AUTOSAR XML (schema 00044)
package /COM/VECTOR/CFG/WORKFLOW/SYSDESC/SYNC
  system SYSTEM: category=ECU_EXTRACT
    system mapping MAPPINGS
      data-mappings:
        sender-receiver-to-signal-mapping={data-element=CComAbsMdl_stubs.COMPOSITIONTYPE.pp_SR_TxBattery_Voltage.Battery_Voltage, system-signal=Battery_Voltage}
        sender-receiver-to-signal-mapping={data-element=CComAbsMdl_stubs.COMPOSITIONTYPE.pp_SR_TxCurrentStateIC.CurrentStateIC, system-signal=CurrentStateIC}
        sender-receiver-to-signal-mapping={data-element=CComAbsMdl_stubs.COMPOSITIONTYPE.pp_SR_TxDebug1_Byte{0..7}.Debug1_Byte{0..7}, system-signal=Debug1_Byte{0..7}}
        sender-receiver-to-signal-mapping={data-element=CComAbsMdl_stubs.COMPOSITIONTYPE.pp_SR_TxDebug2_Byte{0..7}.Debug2_Byte{0..7}, system-signal=Debug2_Byte{0..7}}
        sender-receiver-to-signal-mapping={data-element=CComAbsMdl_stubs.COMPOSITIONTYPE.pp_SR_TxDebug3_Byte{0..7}.Debug3_Byte{0..7}, system-signal=Debug3_Byte{0..7}}
        sender-receiver-to-signal-mapping={data-element=CComAbsMdl_stubs.COMPOSITIONTYPE.pp_SR_TxDebug4_Byte{0..7}.Debug4_Byte{0..7}, system-signal=Debug4_Byte{0..7}}
        sender-receiver-to-signal-mapping={data-element=CComAbsMdl_stubs.COMPOSITIONTYPE.pp_SR_TxDebug5_Byte{0..7}.Debug5_Byte{0..7}, system-signal=Debug5_Byte{0..7}}
        sender-receiver-to-signal-mapping={data-element=CComAbsMdl_stubs.COMPOSITIONTYPE.pp_SR_TxDiag_Buffer_Tx_USDT.Diag_Buffer_Tx_USDT, system-signal=Diag_Buffer_Tx_USDT}
        sender-receiver-to-signal-mapping={data-element=CComAbsMdl_stubs.COMPOSITIONTYPE.pp_SR_TxDiag_Buffer_Tx_UUDT.Diag_Buffer_Tx_UUDT, system-signal=Diag_Buffer_Tx_UUDT}
        sender-receiver-to-signal-mapping={data-element=CComAbsMdl_stubs.COMPOSITIONTYPE.pp_SR_TxFV_Tx.FV_Tx, system-signal=FV_Tx}
        sender-receiver-to-signal-mapping={data-element=CComAbsMdl_stubs.COMPOSITIONTYPE.pp_SR_TxIllumination_PWM.Illumination_PWM, system-signal=Illumination_PWM}
        sender-receiver-to-signal-mapping={data-element=CComAbsMdl_stubs.COMPOSITIONTYPE.pp_SR_TxMAC_Tx.MAC_Tx, system-signal=MAC_Tx}
        sender-receiver-to-signal-mapping={data-element=CComAbsMdl_stubs.COMPOSITIONTYPE.pp_SR_TxOdometer.Odometer, system-signal=Odometer}
        sender-receiver-to-signal-mapping={data-element=CComAbsMdl_stubs.COMPOSITIONTYPE.pp_SR_TxPreviousStateIC.PreviousStateIC, system-signal=PreviousStateIC}
        sender-receiver-to-signal-mapping={data-element=CComAbsMdl_stubs.COMPOSITIONTYPE.pp_SR_TxSecureTxByte{0..3}.SecureTxByte{0..3}, system-signal=SecureTxByte{0..3}}
        sender-receiver-to-signal-mapping={data-element=CComAbsMdl_stubs.COMPOSITIONTYPE.pp_SR_TxUserData{1..5}_IC.UserData{1..5}_IC, system-signal=UserData{1..5}_IC}
        sender-receiver-to-signal-mapping={data-element=CComAbsMdl_stubs.COMPOSITIONTYPE.pp_SR_TxVehicleSpeedIC.VehicleSpeedIC, system-signal=VehicleSpeedIC}
        sender-receiver-to-signal-mapping={data-element=CComAbsMdl_stubs.COMPOSITIONTYPE.rp_SR_RxAmbient_Light_level.Ambient_Light_level, system-signal=Ambient_Light_level}
        sender-receiver-to-signal-mapping={data-element=CComAbsMdl_stubs.COMPOSITIONTYPE.rp_SR_RxDayNightMode.DayNightMode, system-signal=DayNightMode}
        sender-receiver-to-signal-mapping={data-element=CComAbsMdl_stubs.COMPOSITIONTYPE.rp_SR_RxGear.Gear, system-signal=Gear}
        sender-receiver-to-signal-mapping={data-element=CComAbsMdl_stubs.COMPOSITIONTYPE.rp_SR_RxGearMode.GearMode, system-signal=GearMode}
        sender-receiver-to-signal-mapping={data-element=CComAbsMdl_stubs.COMPOSITIONTYPE.rp_SR_RxGearRecommendation.GearRecommendation, system-signal=GearRecommendation}
        sender-receiver-to-signal-mapping={data-element=CComAbsMdl_stubs.COMPOSITIONTYPE.rp_SR_RxGearStatus.GearStatus, system-signal=GearStatus}
        sender-receiver-to-signal-mapping={data-element=CComAbsMdl_stubs.COMPOSITIONTYPE.rp_SR_RxIllumination_level.Illumination_level, system-signal=Illumination_level}
        sender-receiver-to-signal-mapping={data-element=CComAbsMdl_stubs.COMPOSITIONTYPE.rp_SR_RxPowerMode.PowerMode, system-signal=PowerMode}
        sender-receiver-to-signal-mapping={data-element=CComAbsMdl_stubs.COMPOSITIONTYPE.rp_SR_RxTransportMode.TransportMode, system-signal=TransportMode}
        sender-receiver-to-signal-mapping={data-element=CComAbsMdl_stubs.COMPOSITIONTYPE.rp_SR_RxWarning.Warning, system-signal=Warning}
        sender-receiver-to-signal-group-mapping={data-element=TrustecSWC.COMPOSITIONTYPE.RP_RX_SG_ABS.RP_SR_TX_SG_ABS, signal-group=SG_ABS, type-mapping=sender-rec-record-type-mapping=record-element-mappings=[{implementation-record-element=Airbag, system-signal=Airbag}, {implementation-record-element=Alive_101, system-signal=Alive_101}, {implementation-record-element=CRC_101, system-signal=CRC_101}, {implementation-record-element=VehicleSpeedABS, system-signal=VehicleSpeedABS}]}
        sender-receiver-to-signal-group-mapping={data-element=TrustecSWC.COMPOSITIONTYPE.PP_TX_SG_COM_HSSG_COM_HS.SG_COM_HS, signal-group=SG_COM_HS, type-mapping=sender-rec-record-type-mapping=record-element-mappings=[{implementation-record-element=Alive_200, system-signal=Alive_200}, {implementation-record-element=Battery_Voltage, system-signal=Battery_Voltage}, {implementation-record-element=CRC_200, system-signal=CRC_200}]}
        sender-receiver-to-signal-group-mapping={data-element=COMPOSITIONTYPE.PP_TX_SG_COM_HSSG_COM_HS.SG_COM_HS, signal-group=SG_COM_HS, type-mapping=sender-rec-record-type-mapping=record-element-mappings=[{implementation-record-element=Alive_200, system-signal=Alive_200}, {implementation-record-element=Battery_Voltage, system-signal=Battery_Voltage}, {implementation-record-element=CRC_200, system-signal=CRC_200}]}
        sender-receiver-to-signal-group-mapping={data-element=TrustecSWC.COMPOSITIONTYPE.PP_TX_SG_COM_HSSG_COM_HS.SG_COM_HS, signal-group=SG_COM_HS, type-mapping=sender-rec-record-type-mapping=record-element-mappings=[{implementation-record-element=Alive_200, system-signal=Alive_200}, {implementation-record-element=Battery_Voltage, system-signal=Battery_Voltage}, {implementation-record-element=CRC_200, system-signal=CRC_200}]}
        sender-receiver-to-signal-group-mapping={data-element=TrustecSWC.COMPOSITIONTYPE.PP_TX_SG_COM_HS.SG_COM_HS, signal-group=SG_COM_HS, type-mapping=sender-rec-record-type-mapping=record-element-mappings=[{implementation-record-element=Alive_200, system-signal=Alive_200}, {implementation-record-element=Battery_Voltage, system-signal=Battery_Voltage}, {implementation-record-element=CRC_200, system-signal=CRC_200}]}
        sender-receiver-to-signal-mapping={data-element=COMPOSITIONTYPE.rp_SR_RxAmbient_Light_level.Ambient_Light_level, system-signal=Ambient_Light_level}
        sender-receiver-to-signal-mapping={data-element=COMPOSITIONTYPE.rp_SR_RxDayNightMode.DayNightMode, system-signal=DayNightMode}
        sender-receiver-to-signal-mapping={data-element=COMPOSITIONTYPE.rp_SR_RxGear.Gear, system-signal=Gear}
        sender-receiver-to-signal-mapping={data-element=COMPOSITIONTYPE.rp_SR_RxGearMode.GearMode, system-signal=GearMode}
        sender-receiver-to-signal-mapping={data-element=COMPOSITIONTYPE.rp_SR_RxGearRecommendation.GearRecommendation, system-signal=GearRecommendation}
        sender-receiver-to-signal-mapping={data-element=COMPOSITIONTYPE.rp_SR_RxGearStatus.GearStatus, system-signal=GearStatus}
        sender-receiver-to-signal-mapping={data-element=COMPOSITIONTYPE.rp_SR_RxIllumination_level.Illumination_level, system-signal=Illumination_level}
        sender-receiver-to-signal-mapping={data-element=COMPOSITIONTYPE.rp_SR_RxPowerMode.PowerMode, system-signal=PowerMode}
        sender-receiver-to-signal-mapping={data-element=COMPOSITIONTYPE.rp_SR_RxTransportMode.TransportMode, system-signal=TransportMode}
        sender-receiver-to-signal-mapping={data-element=COMPOSITIONTYPE.rp_SR_RxWarning.Warning, system-signal=Warning}
        sender-receiver-to-signal-mapping={data-element=COMPOSITIONTYPE.pp_SR_TxDebug1_Byte{0..7}.Debug1_Byte{0..7}, system-signal=Debug1_Byte{0..7}}
        sender-receiver-to-signal-mapping={data-element=COMPOSITIONTYPE.pp_SR_TxDebug2_Byte{0..7}.Debug2_Byte{0..7}, system-signal=Debug2_Byte{0..7}}
        sender-receiver-to-signal-mapping={data-element=COMPOSITIONTYPE.pp_SR_TxDebug3_Byte{0..7}.Debug3_Byte{0..7}, system-signal=Debug3_Byte{0..7}}
        sender-receiver-to-signal-mapping={data-element=COMPOSITIONTYPE.pp_SR_TxDebug4_Byte{0..7}.Debug4_Byte{0..7}, system-signal=Debug4_Byte{0..7}}
        sender-receiver-to-signal-mapping={data-element=COMPOSITIONTYPE.pp_SR_TxDebug5_Byte{0..7}.Debug5_Byte{0..7}, system-signal=Debug5_Byte{0..7}}
        sender-receiver-to-signal-mapping={data-element=COMPOSITIONTYPE.pp_SR_TxFV_Tx.FV_Tx, system-signal=FV_Tx}
        sender-receiver-to-signal-mapping={data-element=COMPOSITIONTYPE.pp_SR_TxIllumination_PWM.Illumination_PWM, system-signal=Illumination_PWM}
        sender-receiver-to-signal-mapping={data-element=COMPOSITIONTYPE.pp_SR_TxMAC_Tx.MAC_Tx, system-signal=MAC_Tx}
        sender-receiver-to-signal-mapping={data-element=COMPOSITIONTYPE.pp_SR_TxOdometer.Odometer, system-signal=Odometer}
        sender-receiver-to-signal-mapping={data-element=COMPOSITIONTYPE.pp_SR_TxSecureTxByte{0..3}.SecureTxByte{0..3}, system-signal=SecureTxByte{0..3}}
        sender-receiver-to-signal-mapping={data-element=COMPOSITIONTYPE.pp_SR_TxVehicleSpeedIC.VehicleSpeedIC, system-signal=VehicleSpeedIC}
        sender-receiver-to-signal-mapping={data-element=CComAbsMdl_stubs.COMPOSITIONTYPE.rp_SR_RxEngineSpeed.EngineSpeed, system-signal=EngineSpeed}
        sender-receiver-to-signal-mapping={data-element=CComAbsMdl_stubs.COMPOSITIONTYPE.rp_SR_RxTurn_Indicator_Control.Turn_Indicator_Control, system-signal=Turn_Indicator_Control}
        sender-receiver-to-signal-mapping={data-element=CComAbsMdl_stubs.COMPOSITIONTYPE.rp_SR_RxCurrentStateIC.CurrentStateIC, system-signal=CurrentStateIC}
        sender-receiver-to-signal-mapping={data-element=COMPOSITIONTYPE.rp_SR_RxEngineSpeed.EngineSpeed, system-signal=EngineSpeed}
        sender-receiver-to-signal-mapping={data-element=COMPOSITIONTYPE.rp_SR_RxTurn_Indicator_Control.Turn_Indicator_Control, system-signal=Turn_Indicator_Control}
    root-software-compositions:
      root sw composition prototype COMPOSITIONTYPE: flat-map=FLATMAP, software-composition=COMPOSITIONTYPE
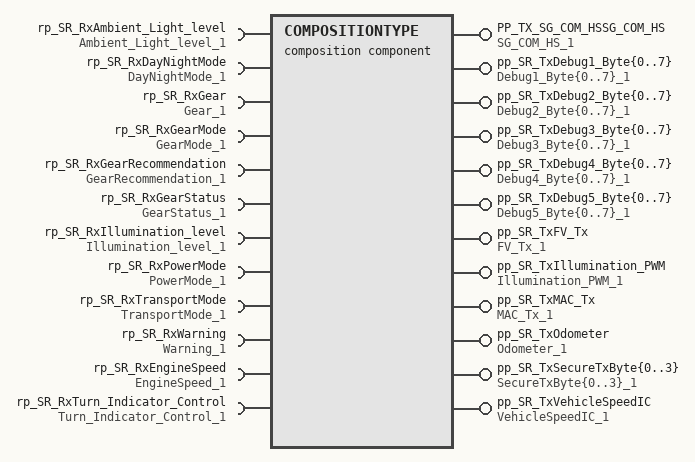
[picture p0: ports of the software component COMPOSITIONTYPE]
  composition sw component type COMPOSITIONTYPE  # UB:Derived from original system description
    provide port PP_TX_SG_COM_HSSG_COM_HS: nonqueued-sender-com-spec{data-element=SG_COM_HS, init-value=fields=[Alive_200:0, Battery_Voltage:0, CRC_200:0]}, provided-interface=SG_COM_HS_1
    10 x require port:
      rp_SR_RxAmbient_Light_level: nonqueued-receiver-com-spec{data-element=Ambient_Light_level, init-value=0}, required-interface=Ambient_Light_level_1
      rp_SR_RxDayNightMode: nonqueued-receiver-com-spec{data-element=DayNightMode, init-value=0}, required-interface=DayNightMode_1
      rp_SR_RxGear: nonqueued-receiver-com-spec{data-element=Gear, init-value=0}, required-interface=Gear_1
      rp_SR_RxGearMode: nonqueued-receiver-com-spec{data-element=GearMode, init-value=0}, required-interface=GearMode_1
      rp_SR_RxGearRecommendation: nonqueued-receiver-com-spec{data-element=GearRecommendation, init-value=0}, required-interface=GearRecommendation_1
      rp_SR_RxGearStatus: nonqueued-receiver-com-spec{data-element=GearStatus, init-value=0}, required-interface=GearStatus_1
      rp_SR_RxIllumination_level: nonqueued-receiver-com-spec{data-element=Illumination_level, init-value=0}, required-interface=Illumination_level_1
      rp_SR_RxPowerMode: nonqueued-receiver-com-spec{data-element=PowerMode, init-value=0}, required-interface=PowerMode_1
      rp_SR_RxTransportMode: nonqueued-receiver-com-spec{data-element=TransportMode, init-value=0}, required-interface=TransportMode_1
      rp_SR_RxWarning: nonqueued-receiver-com-spec{data-element=Warning, init-value=0}, required-interface=Warning_1
    49 x provide port:
      pp_SR_TxDebug1_Byte{0..7}: nonqueued-sender-com-spec{data-element=Debug1_Byte{0..7}, init-value=0}, provided-interface=Debug1_Byte{0..7}_1
      pp_SR_TxDebug2_Byte{0..7}: nonqueued-sender-com-spec{data-element=Debug2_Byte{0..7}, init-value=0}, provided-interface=Debug2_Byte{0..7}_1
      pp_SR_TxDebug3_Byte{0..7}: nonqueued-sender-com-spec{data-element=Debug3_Byte{0..7}, init-value=0}, provided-interface=Debug3_Byte{0..7}_1
      pp_SR_TxDebug4_Byte{0..7}: nonqueued-sender-com-spec{data-element=Debug4_Byte{0..7}, init-value=0}, provided-interface=Debug4_Byte{0..7}_1
      pp_SR_TxDebug5_Byte{0..7}: nonqueued-sender-com-spec{data-element=Debug5_Byte{0..7}, init-value=0}, provided-interface=Debug5_Byte{0..7}_1
      pp_SR_TxFV_Tx: nonqueued-sender-com-spec{data-element=FV_Tx, init-value=0}, provided-interface=FV_Tx_1
      pp_SR_TxIllumination_PWM: nonqueued-sender-com-spec{data-element=Illumination_PWM, init-value=0}, provided-interface=Illumination_PWM_1
      pp_SR_TxMAC_Tx: nonqueued-sender-com-spec{data-element=MAC_Tx, init-value=0}, provided-interface=MAC_Tx_1
      pp_SR_TxOdometer: nonqueued-sender-com-spec{data-element=Odometer, init-value=0}, provided-interface=Odometer_1
      pp_SR_TxSecureTxByte{0..3}: nonqueued-sender-com-spec{data-element=SecureTxByte{0..3}, init-value=0}, provided-interface=SecureTxByte{0..3}_1
      pp_SR_TxVehicleSpeedIC: nonqueued-sender-com-spec{data-element=VehicleSpeedIC, init-value=0}, provided-interface=VehicleSpeedIC_1
    require port rp_SR_RxEngineSpeed: nonqueued-receiver-com-spec{data-element=EngineSpeed, init-value=0}, required-interface=EngineSpeed_1
    require port rp_SR_RxTurn_Indicator_Control: nonqueued-receiver-com-spec{data-element=Turn_Indicator_Control, init-value=0}, required-interface=Turn_Indicator_Control_1
    80 x component:
      UclProxyCdd: type=UclProxyCdd
      Test_Comp: type=Test_Comp
      DemMaster_0: type=DemMaster_0
      DemSatellite_0: type=DemSatellite_0
      NvBlockSwComponentType: type=NvBlockSwComponentType
      NvM: type=NvM
      NvMExt: type=NvMExt
      EcuMExt: type=EcuMExt
      TmExt: type=TmExt
      IoHwAb: type=IoHwAb
      MemAbstractStub: type=MemAbstractStub
      EcuAppM: type=EcuAppM
      EcuM: type=EcuM
      MemAbstractMdl: type=MemAbstractMdl
      DmnMgr: type=DmnMgr
      SciDrv: type=SciDrv
      CBacklightCdd: type=CBacklightCdd
      CDisplayCdd: type=CDisplayCdd
      CCDD_EcuPowerM: type=CCDD_EcuPowerM
      Dlt: type=Dlt
      DltExt: type=DltExt
      RtcCdd: type=RtcCdd
      DcmExt: type=DcmExt
      DemExt: type=DemExt
      CMeetCdd: type=CMeetCdd
      GdtCdd: type=GdtCdd
      WdgM: type=WdgM
      DcmApp: type=DcmApp
      DemApp: type=DemApp
      SafeBsw: type=SafeBsw
      Os_OsCore0_swc: type=Os_OsCore0_swc
      CPmicCdd: type=CPmicCdd
      CIoExp: type=CIoExp
      CComAbsMdl: type=CComAbsMdl
      CComAbsCtrl: type=CComAbsCtrl
      CCtrl_Telltale: type=CCtrl_Telltale
      Ctrl_Dim: type=Ctrl_Dim
      Ctrl_warning: type=Ctrl_warning
      Ctrl_WSS: type=Ctrl_WSS
      CView_Telltale: type=CView_Telltale
      CWarnMsg_Core_Observer: type=CWarnMsg_Core_Observer
      FastGaugeAdapter: type=FastGaugeAdapter
      Mdl_Airbag: type=Mdl_Airbag
      Mdl_Dim: type=Mdl_Dim
      Mdl_Gear: type=Mdl_Gear
      Mdl_Linear_Interpolation: type=Mdl_Linear_Interpolation
      Mdl_SafetyAdapter: type=Mdl_SafetyAdapter
      Mdl_Speed: type=Mdl_Speed
      Mdl_Tacho: type=Mdl_Tacho
      Mdl_TurnHazard: type=Mdl_TurnHazard
      Mdl_wFuelLidOpen: type=Mdl_wFuelLidOpen
      Mdl_wAirbag: type=Mdl_wAirbag
      View_Speed: type=View_Speed
      SlowGaugeAdapter: type=SlowGaugeAdapter
      WarnMsg_Core_TmrSupport: type=WarnMsg_Core_TmrSupport
      Det: type=Det
      ComMExt: type=ComMExt
      CorTst: type=CorTst
      FlsTst: type=FlsTst
      NvMExtSf: type=NvMExtSf
      RamTst: type=RamTst
      SysTst: type=SysTst
      CFltM: type=CFltM
      CUpdateCdd: type=CUpdateCdd
      SafeNvM: type=SafeNvM
      MemAbstract_Stub_Safe: type=MemAbstract_Stub_Safe
      ComCallout: type=ComCallout
      CFltMExt: type=CFltMExt
      CCDD_BswFit: type=CCDD_BswFit
      CCDD_FitManager: type=CCDD_FitManager
      CCDD_McuFit: type=CCDD_McuFit
      Ctrl_Illumination: type=Ctrl_Illumination
      View_Illumination: type=View_Illumination
      CComAbsMdl_stubs: type=CComAbsMdl_stubs
      CComAbsMdlSafe: type=CComAbsMdlSafe
      TrustecSWC: type=TrustecSWC
      CRstM: type=CRstM
      CSigCdd: type=CSigCdd
      CSwcDispMonSf: type=CSwcDispMonSf
      CCDD_EcuBatteryM: type=CCDD_EcuBatteryM
    connect MemAbstractStub.NvMSampleBlock1_NvMNotifyJobFinished_1 -> NvM.NvM_RpNotifyJobEnd_NvBlockSwComponentTypeNVBlockDescriptor_NvMSampleBlock1
    connect MemAbstractStub.SampleBlock2_NvMNotifyJobFinished_1 -> NvM.NvM_RpNotifyJobEnd_NvBlockSwComponentTypeNVBlockDescriptor_SampleBlock2
    connect MemAbstractStub.NvMSampleBlock1_NvMNotifyJobFinished -> NvM.NvM_RpNotifyJobEnd_NvBlockSwComponentTypeNVBlockDescriptor_NvMSampleBlock1
    connect MemAbstractStub.SampleBlock2_NvMNotifyJobFinished -> NvM.NvM_RpNotifyJobEnd_NvBlockSwComponentTypeNVBlockDescriptor_SampleBlock2
    connect EcuAppM.ppCS_EcuAppM -> EcuMExt.rpCS_EcuAppM  # UB:Derived from original system description
    connect MemAbstractStub.BsConst_Audio_NvMNotifyJobFinished -> NvM.NvM_RpNotifyJobEnd_NvBlockSwComponentTypeNVBlockDescriptor_BsConst_Audio
    connect MemAbstractStub.BsConst_Communication_NvMNotifyJobFinished -> NvM.NvM_RpNotifyJobEnd_NvBlockSwComponentTypeNVBlockDescriptor_BsConst_Communication
    connect MemAbstractStub.BsConst_EngOffTimer_NvMNotifyJobFinished -> NvM.NvM_RpNotifyJobEnd_NvBlockSwComponentTypeNVBlockDescriptor_BsConst_EngOffTimer
    connect MemAbstractStub.BsConst_FuelGauge_NvMNotifyJobFinished -> NvM.NvM_RpNotifyJobEnd_NvBlockSwComponentTypeNVBlockDescriptor_BsConst_FuelGauge
    connect MemAbstractStub.BsConst_Illumination_NvMNotifyJobFinished -> NvM.NvM_RpNotifyJobEnd_NvBlockSwComponentTypeNVBlockDescriptor_BsConst_Illumination
    connect MemAbstractStub.BsConst_OilGauge_NvMNotifyJobFinished -> NvM.NvM_RpNotifyJobEnd_NvBlockSwComponentTypeNVBlockDescriptor_BsConst_OilGauge
    connect MemAbstractStub.BsConst_PowerGauge_NvMNotifyJobFinished -> NvM.NvM_RpNotifyJobEnd_NvBlockSwComponentTypeNVBlockDescriptor_BsConst_PowerGauge
    connect MemAbstractStub.BsConst_Power_NvMNotifyJobFinished -> NvM.NvM_RpNotifyJobEnd_NvBlockSwComponentTypeNVBlockDescriptor_BsConst_Power
    connect MemAbstractStub.BsConst_RealTimeClock_NvMNotifyJobFinished -> NvM.NvM_RpNotifyJobEnd_NvBlockSwComponentTypeNVBlockDescriptor_BsConst_RealTimeClock
    connect MemAbstractStub.BsConst_ServiceReminder_NvMNotifyJobFinished -> NvM.NvM_RpNotifyJobEnd_NvBlockSwComponentTypeNVBlockDescriptor_BsConst_ServiceReminder
    connect MemAbstractStub.BsConst_SpeedoGauge_NvMNotifyJobFinished -> NvM.NvM_RpNotifyJobEnd_NvBlockSwComponentTypeNVBlockDescriptor_BsConst_SpeedoGauge
    connect MemAbstractStub.BsConst_TachoGauge_NvMNotifyJobFinished -> NvM.NvM_RpNotifyJobEnd_NvBlockSwComponentTypeNVBlockDescriptor_BsConst_TachoGauge
    connect MemAbstractStub.BsConst_TempGauge_NvMNotifyJobFinished -> NvM.NvM_RpNotifyJobEnd_NvBlockSwComponentTypeNVBlockDescriptor_BsConst_TempGauge
    connect MemAbstractStub.BsConst_TripComputer_NvMNotifyJobFinished -> NvM.NvM_RpNotifyJobEnd_NvBlockSwComponentTypeNVBlockDescriptor_BsConst_TripComputer
    connect MemAbstractStub.BsConst_Warning_NvMNotifyJobFinished -> NvM.NvM_RpNotifyJobEnd_NvBlockSwComponentTypeNVBlockDescriptor_BsConst_Warning
    connect MemAbstractStub.BsCys_Certicificate_NvMNotifyJobFinished -> NvM.NvM_RpNotifyJobEnd_NvBlockSwComponentTypeNVBlockDescriptor_BsCys_Certicificate
    connect MemAbstractStub.BsDiag_ErrorRecord_NvMNotifyJobFinished -> NvM.NvM_RpNotifyJobEnd_NvBlockSwComponentTypeNVBlockDescriptor_BsDiag_ErrorRecord
    connect MemAbstractStub.BsFuSa_Audio_NvMNotifyJobFinished -> NvM.NvM_RpNotifyJobEnd_NvBlockSwComponentTypeNVBlockDescriptor_BsFuSa_Audio
    connect MemAbstractStub.BsFuSa_Communication_NvMNotifyJobFinished -> NvM.NvM_RpNotifyJobEnd_NvBlockSwComponentTypeNVBlockDescriptor_BsFuSa_Communication
    connect MemAbstractStub.BsFuSa_Config_NvMNotifyJobFinished -> NvM.NvM_RpNotifyJobEnd_NvBlockSwComponentTypeNVBlockDescriptor_BsFuSa_Config
    connect MemAbstractStub.BsFuSa_Display_NvMNotifyJobFinished -> NvM.NvM_RpNotifyJobEnd_NvBlockSwComponentTypeNVBlockDescriptor_BsFuSa_Display
    connect MemAbstractStub.BsFuSa_Power_NvMNotifyJobFinished -> NvM.NvM_RpNotifyJobEnd_NvBlockSwComponentTypeNVBlockDescriptor_BsFuSa_Power
    connect MemAbstractStub.BsFuSa_Warning_NvMNotifyJobFinished -> NvM.NvM_RpNotifyJobEnd_NvBlockSwComponentTypeNVBlockDescriptor_BsFuSa_Warning
    connect MemAbstractStub.BsFusa_Fota_NvMNotifyJobFinished -> NvM.NvM_RpNotifyJobEnd_NvBlockSwComponentTypeNVBlockDescriptor_BsFusa_Fota
    connect MemAbstractStub.BsReten_Audio_NvMNotifyJobFinished -> NvM.NvM_RpNotifyJobEnd_NvBlockSwComponentTypeNVBlockDescriptor_BsReten_Audio
    connect MemAbstractStub.BsReten_Communication_NvMNotifyJobFinished -> NvM.NvM_RpNotifyJobEnd_NvBlockSwComponentTypeNVBlockDescriptor_BsReten_Communication
    connect MemAbstractStub.BsReten_Display_NvMNotifyJobFinished -> NvM.NvM_RpNotifyJobEnd_NvBlockSwComponentTypeNVBlockDescriptor_BsReten_Display
    connect MemAbstractStub.BsReten_Gauges_NvMNotifyJobFinished -> NvM.NvM_RpNotifyJobEnd_NvBlockSwComponentTypeNVBlockDescriptor_BsReten_Gauges
    connect MemAbstractStub.BsReten_Illumination_NvMNotifyJobFinished -> NvM.NvM_RpNotifyJobEnd_NvBlockSwComponentTypeNVBlockDescriptor_BsReten_Illumination
    connect MemAbstractStub.BsReten_Odometer_NvMNotifyJobFinished -> NvM.NvM_RpNotifyJobEnd_NvBlockSwComponentTypeNVBlockDescriptor_BsReten_Odometer
    connect MemAbstractStub.BsReten_Personalization_NvMNotifyJobFinished -> NvM.NvM_RpNotifyJobEnd_NvBlockSwComponentTypeNVBlockDescriptor_BsReten_Personalization
    connect MemAbstractStub.BsReten_Power_NvMNotifyJobFinished -> NvM.NvM_RpNotifyJobEnd_NvBlockSwComponentTypeNVBlockDescriptor_BsReten_Power
    connect MemAbstractStub.BsReten_RealTimeClock_NvMNotifyJobFinished -> NvM.NvM_RpNotifyJobEnd_NvBlockSwComponentTypeNVBlockDescriptor_BsReten_RealTimeClock
    connect MemAbstractStub.BsReten_Tripcomputer_NvMNotifyJobFinished -> NvM.NvM_RpNotifyJobEnd_NvBlockSwComponentTypeNVBlockDescriptor_BsReten_Tripcomputer
    connect MemAbstractStub.BsReten_VisDlt_NvMNotifyJobFinished -> NvM.NvM_RpNotifyJobEnd_NvBlockSwComponentTypeNVBlockDescriptor_BsReten_VisDlt
    connect MemAbstractStub.BsReten_Warning_NvMNotifyJobFinished -> NvM.NvM_RpNotifyJobEnd_NvBlockSwComponentTypeNVBlockDescriptor_BsReten_Warning
    connect MemAbstractStub.BsRt_CusDlt_NvMNotifyJobFinished -> NvM.NvM_RpNotifyJobEnd_NvBlockSwComponentTypeNVBlockDescriptor_BsRt_CusDlt
    connect MemAbstractStub.BsRt_FuelGauge_NvMNotifyJobFinished -> NvM.NvM_RpNotifyJobEnd_NvBlockSwComponentTypeNVBlockDescriptor_BsRt_FuelGauge
    connect MemAbstractStub.BsRt_Illumination_NvMNotifyJobFinished -> NvM.NvM_RpNotifyJobEnd_NvBlockSwComponentTypeNVBlockDescriptor_BsRt_Illumination
    connect MemAbstractStub.BsRt_Odometer_NvMNotifyJobFinished -> NvM.NvM_RpNotifyJobEnd_NvBlockSwComponentTypeNVBlockDescriptor_BsRt_Odometer
    connect MemAbstractStub.BsRt_OilGauge_NvMNotifyJobFinished -> NvM.NvM_RpNotifyJobEnd_NvBlockSwComponentTypeNVBlockDescriptor_BsRt_OilGauge
    connect MemAbstractStub.BsRt_Personalization_NvMNotifyJobFinished -> NvM.NvM_RpNotifyJobEnd_NvBlockSwComponentTypeNVBlockDescriptor_BsRt_Personalization
    connect MemAbstractStub.BsRt_PowerGauge_NvMNotifyJobFinished -> NvM.NvM_RpNotifyJobEnd_NvBlockSwComponentTypeNVBlockDescriptor_BsRt_PowerGauge
    connect MemAbstractStub.BsRt_RealTimeClock_NvMNotifyJobFinished -> NvM.NvM_RpNotifyJobEnd_NvBlockSwComponentTypeNVBlockDescriptor_BsRt_RealTimeClock
    connect MemAbstractStub.BsRt_SpeedoGauge_NvMNotifyJobFinished -> NvM.NvM_RpNotifyJobEnd_NvBlockSwComponentTypeNVBlockDescriptor_BsRt_SpeedoGauge
    connect MemAbstractStub.BsRt_TachoGauge_NvMNotifyJobFinished -> NvM.NvM_RpNotifyJobEnd_NvBlockSwComponentTypeNVBlockDescriptor_BsRt_TachoGauge
    connect MemAbstractStub.BsRt_TempGauge_NvMNotifyJobFinished -> NvM.NvM_RpNotifyJobEnd_NvBlockSwComponentTypeNVBlockDescriptor_BsRt_TempGauge
    connect MemAbstractStub.BsRt_TripComputer_NvMNotifyJobFinished -> NvM.NvM_RpNotifyJobEnd_NvBlockSwComponentTypeNVBlockDescriptor_BsRt_TripComputer
    connect MemAbstractStub.BsRt_Warning_NvMNotifyJobFinished -> NvM.NvM_RpNotifyJobEnd_NvBlockSwComponentTypeNVBlockDescriptor_BsRt_Warning
    connect MemAbstractStub.BsShare_EcuPartNumber_NvMNotifyJobFinished -> NvM.NvM_RpNotifyJobEnd_NvBlockSwComponentTypeNVBlockDescriptor_BsShare_EcuPartNumber
    connect MemAbstractStub.BsShare_SwUpdFotaFinPrint_NvMNotifyJobFinished -> NvM.NvM_RpNotifyJobEnd_NvBlockSwComponentTypeNVBlockDescriptor_BsShare_SwUpdFotaFinPrint
    connect MemAbstractStub.BsShare_SwUpdFotaMode_NvMNotifyJobFinished -> NvM.NvM_RpNotifyJobEnd_NvBlockSwComponentTypeNVBlockDescriptor_BsShare_SwUpdFotaMode
    connect MemAbstractStub.BsShare_SwUpdFotaStatus_NvMNotifyJobFinished -> NvM.NvM_RpNotifyJobEnd_NvBlockSwComponentTypeNVBlockDescriptor_BsShare_SwUpdFotaStatus
    connect MemAbstractStub.BsShare_SwUpdFotadecrypt_NvMNotifyJobFinished -> NvM.NvM_RpNotifyJobEnd_NvBlockSwComponentTypeNVBlockDescriptor_BsShare_SwUpdFotadecrypt
    connect MemAbstractStub.BsShare_SwUpdReflash_NvMNotifyJobFinished -> NvM.NvM_RpNotifyJobEnd_NvBlockSwComponentTypeNVBlockDescriptor_BsShare_SwUpdReflash
    connect MemAbstractStub.BsShare_VehicleConfig_NvMNotifyJobFinished -> NvM.NvM_RpNotifyJobEnd_NvBlockSwComponentTypeNVBlockDescriptor_BsShare_VehicleConfig
    connect MemAbstractStub.BsShare_VisMeet_NvMNotifyJobFinished -> NvM.NvM_RpNotifyJobEnd_NvBlockSwComponentTypeNVBlockDescriptor_BsShare_VisMeet
    connect MemAbstractStub.RefCys_Certicificate1_NvMNotifyJobFinished -> NvM.NvM_RpNotifyJobEnd_NvBlockSwComponentTypeNVBlockDescriptor_RefCys_Certicificate1
    connect MemAbstractStub.BsDiag_Dtc_NvMNotifyJobFinished -> NvM.NvM_RpNotifyJobEnd_NvBlockSwComponentTypeNVBlockDescriptor_BsDiag_Dtc
    connect MemAbstractStub.RefCys_Certicificate_NvMNotifyJobFinished -> NvM.NvM_RpNotifyJobEnd_NvBlockSwComponentTypeNVBlockDescriptor_RefCys_Certicificate
    connect DmnMgr.pp_CmpLibCmd_CDmnMgr -> EcuAppM.rp_CmpLibCmd_rp_CmpLibCmd_CDmnMgr  # UB:Derived from original system description
    connect UclProxyCdd.pSR_HealthDomainFatalError -> DmnMgr.rSR_HealthDomainFatalError
    connect UclProxyCdd.pSR_HealthDomainHeartbeat -> DmnMgr.rSR_HealthDomainHeartbeat
    connect UclProxyCdd.pSR_HealthDumpHdrInfo -> DmnMgr.rSR_HealthDumpHdrInfo
    connect UclProxyCdd.pSR_PowerExtendShutdownTime -> DmnMgr.rSR_PowerExtendShutdownTime
    connect UclProxyCdd.pSR_PowerSystemState -> DmnMgr.rSR_PowerSystemState
    connect UclProxyCdd.pSR_HealthDumpData -> DmnMgr.rSR_HealthDumpData  # UB:Derived from original system description
    connect UclProxyCdd.pSR_PowerKeepSystemAwake -> DmnMgr.rSR_PowerKeepSystemAwake  # UB:Derived from original system description
    connect UclProxyCdd.ppCS_UclInitShutdown -> DmnMgr.rpCS_UclInitShutdown  # UB:Derived from original system description
    connect UclProxyCdd.pp_CmpLibCmd_CUclProxyCdd -> EcuAppM.rp_CmpLibCmd_rp_CmpLibCmd_CUclProxyCdd  # UB:Derived from original system description
    connect UclProxyCdd.pSR_HealthDomainFatalError -> Test_Comp.pSR_HealthDomainFatalError
    connect UclProxyCdd.pSR_HealthDomainHeartbeat -> Test_Comp.pSR_HealthDomainHeartbeat
    connect UclProxyCdd.pSR_HealthDumpHdrInfo -> Test_Comp.pSR_HealthDumpHdrInfo
    connect UclProxyCdd.pSR_HealthEventRecord -> Test_Comp.pSR_HealthEventRecord
    connect UclProxyCdd.pSR_PowerExtendShutdownTime -> Test_Comp.pSR_PowerExtendShutdownTime
    connect UclProxyCdd.pSR_PowerSystemState -> Test_Comp.pSR_PowerSystemState
    connect Test_Comp.rSR_HealthDumpGetData -> UclProxyCdd.rSR_HealthDumpGetData
    connect Test_Comp.rSR_HealthDumpGetHdr -> UclProxyCdd.rSR_HealthDumpGetHdr
    connect Test_Comp.rSR_IgnState -> UclProxyCdd.rSR_IgnState
    connect Test_Comp.rSR_PowerSystemStateReqChange -> UclProxyCdd.rSR_PowerSystemStateReqChange
    connect DmnMgr.pSR_HealthDumpGetData -> UclProxyCdd.rSR_HealthDumpGetData  # UB:Derived from original system description
    connect DmnMgr.pSR_HealthDumpGetHdr -> UclProxyCdd.rSR_HealthDumpGetHdr  # UB:Derived from original system description
    connect DmnMgr.pSR_PowerSystemStateReqChange -> UclProxyCdd.rSR_PowerSystemStateReqChange  # UB:Derived from original system description
    connect DmnMgr.ppCS_UclSystemCallbacks -> UclProxyCdd.rCS_UclSystemCallbacks  # UB:Derived from original system description
    connect DmnMgr.ppSR_DmnInfo -> DmnMgr.rpSR_DmnInfo  # UB:Derived from original system description
    connect UclProxyCdd.pSR_HealthDomainFatalError -> DmnMgr.rSR_HealthDomainFatalError  # UB:Derived from original system description
    connect UclProxyCdd.pSR_HealthDomainHeartbeat -> DmnMgr.rSR_HealthDomainHeartbeat  # UB:Derived from original system description
    connect UclProxyCdd.pSR_HealthDumpHdrInfo -> DmnMgr.rSR_HealthDumpHdrInfo  # UB:Derived from original system description
    connect UclProxyCdd.pSR_PowerExtendShutdownTime -> DmnMgr.rSR_PowerExtendShutdownTime  # UB:Derived from original system description
    connect IoHwAb.ppIoHwAb_DOut -> CCDD_EcuPowerM.rpIoHwAb_DOut  # UB:Derived from original system description
    connect IoHwAb.ppIoHwAb_Din -> CCDD_EcuPowerM.rpIoHwAb_Din  # UB:Derived from original system description
    connect IoHwAb.ppIoHwAb_PWM -> CCDD_EcuPowerM.rpIoHwAb_PWM  # UB:Derived from original system description
    connect IoHwAb.ppIoHwAb_PWM -> CBattMdl.rpIoHwAb_PWM
    connect IoHwAb.ppIoHwAb_ADC -> CCDD_EcuPowerM.rpIoHwAb_ADC  # UB:Derived from original system description
    connect MemAbstractMdl.pp_CS_MemAbsGet -> DltExt.rp_CS_MemAbsGet  # UB:Derived from original system description
    connect MemAbstractMdl.pp_CS_MemAbsSet -> DltExt.rp_CS_MemAbsSet  # UB:Derived from original system description
    connect MemAbstractMdl.pp_CS_MemAbs_NvMWriteStatus -> DltExt.rp_CS_MemAbs_NvMWriteStatus  # UB:Derived from original system description
    connect UclProxyCdd.pSR_PowerSystemState -> DmnMgr.rSR_PowerSystemState  # UB:Derived from original system description
    connect CBacklightCdd.pp_CS_Backlight_Notify -> CDisplayCdd.rp_CS_Backlight_Notify
    connect CBacklightCdd.pp_CS_Backlight_Status -> CDisplayCdd.rp_CS_Backlight_Status
    connect CBacklightCdd.pp_CS_Backlight_service -> EcuAppM.rp_CS_Backlight_service
    connect CBacklightCdd.pp_CmpLibCmd_CBacklightCdd -> EcuAppM.rp_CmpLibCmd_rp_CmpLibCmd_CBacklightCdd
    connect IoHwAb.ppIoHwAb_DOut -> CBacklightCdd.rpIoHwAb_DOut
    connect IoHwAb.ppIoHwAb_Din -> CBacklightCdd.rpIoHwAb_Din
    connect IoHwAb.ppIoHwAb_PWM -> CBacklightCdd.rpIoHwAb_PWM
    connect IoHwAb.ppIoHwAb_DOut -> CDisplayCdd.rpIoHwAb_SetDout
    connect CRtcCdd.pp_CmpLibCmd_CRTCCdd -> EcuAppM.rp_CmpLibCmd_rp_CmpLibCmd_CRTCCdd
    connect IoHwAb.ppIoHwAb_ADC -> CRtcCdd.rp_CS_IoHwAb_ADC
    connect IoHwAb.ppIoHwAb_DOut -> CRtcCdd.rp_IoHwAb_DOut
    connect IoHwAb.ppIoHwAb_Din -> CRtcCdd.rp_IoHwAb_Din
    connect CBattMdl.pp_CmpLibCmd_CBattMdl -> EcuAppM.rp_CmpLibCmd_rp_CmpLibCmd_CBattMdl
    connect CCDD_EcuPowerM.pp_CmpLibCmd -> EcuAppM.rp_CmpLibCmd_rp_CmpLibCmd_CCDD_EcuPowerM
    connect CCDD_EcuPowerM.ppCS_RequestPower -> EcuAppM.rpCS_RequestPower
    connect CCDD_EcuPowerM.pp_CmpLibCmd_CCDD_EcuPowerM -> EcuAppM.rp_CmpLibCmd_rp_CmpLibCmd_CCDD_EcuPowerM
    connect EcuMExt.ppCS_EcumExt_ReleaseRUN -> EcuAppM.rpCS_EcumExt_ReleaseRUN
    connect EcuMExt.ppCS_EcumExt_RequestRUN -> EcuAppM.rpCS_EcumExt_RequestRUN
    connect NvMExt.pp_CS_NvMExt_GetNvMExtReadAllStatus -> EcuAppM.rp_CS_NvMExt_GetNvMExtReadAllStatus
    connect NvMExt.pp_CS_NvMExt_SleepOperations -> EcuAppM.rp_CS_NvMExt_SleepOperations
    connect NvMExt.pp_CS_NvmExtStartReadAll -> EcuAppM.rp_CS_NvmExtStartReadAll
    connect RtcCdd.pp_CmpLibCmd_CRTCCdd -> EcuAppM.rp_CmpLibCmd_rp_CmpLibCmd_CRTCCdd
    connect IoHwAb.ppIoHwAb_ADC -> RtcCdd.rp_CS_IoHwAb_ADC
    connect IoHwAb.ppIoHwAb_DOut -> RtcCdd.rp_IoHwAb_DOut
    connect IoHwAb.ppIoHwAb_Din -> RtcCdd.rp_IoHwAb_Din
    connect MemAbstractMdl.pp_CS_MemAbsGet -> DcmExt.rp_CS_MemAbsGet
    connect MemAbstractMdl.pp_CS_MemAbsSet -> DcmExt.rp_CS_MemAbsSet
    connect MemAbstractMdl.pp_SR_JobStatus -> DcmExt.rp_SR_JobStatus
    connect MemAbstractMdl.pp_CmpLibCmd_MemAbstractMdl -> EcuAppM.rp_CmpLibCmd_rp_CmpLibCmd_MemAbstractMdl
    connect UclProxyCdd.pSR_DisplayCurrentState -> Test_Comp.pSR_DisplayCurrentState
    connect CMeetCdd.pp_CS_DID_DiagAction -> DcmExt.rp_CS_DID_DiagAction
    connect CMeetCdd.pp_CS_RID_DiagAction -> DcmExt.rp_CS_RID_DiagAction
    connect CMeetCdd.pp_CmpLibCmd_MeetCdd -> EcuAppM.rp_CmpLibCmd_rp_CmpLibCmd_MeetCdd
    connect IoHwAb.ppIoHwAb_ADC -> CMeetCdd.rpIoHwAb_ADC
    connect IoHwAb.ppIoHwAb_DOut -> CMeetCdd.rpIoHwAb_DOut
    connect IoHwAb.ppIoHwAb_Din -> CMeetCdd.rpIoHwAb_Din
    connect IoHwAb.ppIoHwAb_PWM -> CMeetCdd.rpIoHwAb_PWM
    connect MemAbstractMdl.pp_CS_MemAbsGet -> CMeetCdd.rp_CS_MemAbsGet
    connect MemAbstractMdl.pp_CS_MemAbsSet -> CMeetCdd.rp_CS_MemAbsSet
    connect MemAbstractMdl.pp_SR_JobStatus -> CMeetCdd.rp_SR_JobStatus
    connect GdtCdd.pp_CmpLibCmd_CGdtCdd -> EcuAppM.rp_CmpLibCmd_rp_CmpLibCmd_CGdtCdd
    connect TmExt.pp_CS_TmExt_Timer_Start -> GdtCdd.rp_GdtCddTimer_Start
    connect TmExt.pp_CS_TmExt_Timer_GetElapsedTime -> GdtCdd.rp_GdtCddTimer_getElapsedTime
    connect TmExt.pp_CS_TmExt_Timer_Stop -> GdtCdd.rp_GdtTimerStop
    connect DcmApp.pp_CS_DID_App_Diag_Action -> DcmExt.rp_CS_DID_App_DiagAction
    connect DcmApp.pp_CS_DiagEntryStatus -> DcmExt.rp_CS_DiagEntryStatus
    connect DcmApp.pp_CS_RID_App_Diag_Action -> DcmExt.rp_CS_RID_App_DiagAction
    connect DcmApp.pp_CmpLibCmd_CDcmApp -> EcuAppM.rp_CmpLibCmd_rp_CmpLibCmd_CDcmArp
    connect DemApp.pp_CmpLibCmd_CDemApp -> EcuAppM.rp_CmpLibCmd_rp_CmpLibCmd_CDemArp
    connect DemExt.pp_CS_DemExt_ClearDTC -> DemApp.rp_CS_DemExt_ClearDTC
    connect DemExt.pp_CS_DemExt_SetEventStatus -> DemApp.rp_CS_DemExt_SetEventStatus
    connect DemExt.pp_CS_DemExt_SetOperationCycleState -> DemApp.rp_CS_DemExt_SetOperationCycleState
    connect EcuAppM.ppSRDisplaySetPower -> UclProxyCdd.rSR_DisplaySetPower
    connect UclProxyCdd.pSR_DisplayCurrentState -> EcuAppM.rpSRDisplayCurrentState
    connect CIoExp.pp_CmpLibCmd_CIoExp -> EcuAppM.rp_CmpLibCmd_rp_CmpLibCmd_CIoExp
    connect CPmicCdd.pp_CmpLibCmd_CPmicCdd -> EcuAppM.rp_CmpLibCmd_rp_CmpLibCmd_CPmicCdd
    connect CBattMdl.ppSR_BattMdl_AVP -> CCtrl_Telltale.rpSR_BattMdl_AVP
    connect CComAbsCtrl.pp_CmpLibCmd_CComAbsCtrl -> EcuAppM.rp_CmpLibCmd_rp_CmpLibCmd_CComAbsCtrl
    connect CCtrl_Telltale.ppBlinkStatusArray -> CView_Telltale.rpBlinkStatusArray
    connect CCtrl_Telltale.ppTelltaleStatusOP -> CView_Telltale.rpTelltaleStatusOP
    connect Ctrl_Dim.pSR_IlluminationData -> UclProxyCdd.rSR_IlluminationData
    connect Ctrl_Dim.pp_Ctrl_Ready_to_Sleep -> Mdl_Dim.rp_Ctrl_Ready_to_Sleep
    connect Ctrl_Dim.pp_GetCurrent_Duty -> Mdl_Dim.rp_Current_duty
    connect Ctrl_Dim.pp_IlumDayNightRequired -> Mdl_Dim.rp_IlumDayNightRequired
    connect Ctrl_Dim.pp_IlumDayNightStatus -> Mdl_Dim.rp_IlumDayNightStatus
    connect Ctrl_Dim.pp_StopPwmUpdate -> Mdl_Dim.rp_StopPwmUpdate
    connect Ctrl_Dim.pp_UpdatePwmDirect -> Mdl_Dim.rp_UpdatePwmDirect
    connect Ctrl_Dim.pp_UpdatePwmWithTime -> Mdl_Dim.rp_PwmWithTime
    connect Ctrl_Dim.pp_UpdatePwmWithTimeExp -> Mdl_Dim.rp_PwmWithTimeExp
    connect Mdl_Dim.pp_IlumStep -> Ctrl_Dim.rp_IlumStep
    connect IoHwAb.ppIoHwAb_PWM -> Ctrl_Dim.rp_PwmSetDuty
    connect Mdl_Dim.pp_RheostatDayStep -> Ctrl_Dim.rp_RheostatDayStep
    connect Mdl_Dim.pp_RheostatNightStep -> Ctrl_Dim.rp_RheostatNightStep
    connect Mdl_Dim.pp_illum_rheostat_change -> Ctrl_Dim.rp_Rheostat_Change
    connect Ctrl_warning.ppActiveWarningStatus -> CWarnMsg_Core_Observer.rpActiveWarningStatus
    connect Ctrl_warning.ppCtrlWarningStatus -> Mdl_Dim.rpUpdateDIMWarning
    connect Ctrl_warning.ppWarnDisplayPayload -> CWarnMsg_Core_Observer.rp_UpdateDisplayPayload
    connect Ctrl_warning.ppWarnDisplayStatus -> CWarnMsg_Core_Observer.rp_UpdateDisplayStatus
    connect Ctrl_warning.ppWarningActiveStatus -> CWarnMsg_Core_Observer.rp_ActiveWarningSts
    connect Ctrl_WSS.ppIgnSubstate -> View_Speed.rpIgnSubstate
    connect Ctrl_WSS.pp_AppMdl_Sleep -> Mdl_Dim.rp_ILL_ReadyToSleep
    connect Ctrl_WSS.pp_ClusterMode -> View_Speed.rp_ClusterMode
    connect Ctrl_WSS.pp_HMIReady -> CView_Telltale.rp_HMIReady
    connect Ctrl_WSS.pp_TFTDisplayOn -> Mdl_Dim.rp_TFTDisplayOn
    connect Ctrl_WSS.pp_Variant_status -> Mdl_Gear.rp_Variant_Status
    connect Ctrl_WSS.pp_VehicleAppMode -> Mdl_Gear.rpVehicleAppMode
    connect MemAbstractMdl.pp_CS_MemAbs_NvMWriteStatus -> Ctrl_WSS.rp_CS_MemAbs_NvMWriteStatus
    connect NvMExt.pp_CS_NvMExt_GetNvMExtReadAllStatus -> Ctrl_WSS.rp_CS_NvMExt_GetNvMExtReadAllStatus
    connect NvMExt.pp_CS_NvMExt_SleepOperations -> Ctrl_WSS.rp_CS_NvMExt_SleepOperations
    connect Mdl_Dim.pp_IlumDayNightStatus -> Ctrl_WSS.rp_IlumDayNightStatus
    connect Mdl_Gear.pp_ShiftPositionDisplay -> Ctrl_WSS.rp_ShiftPositionDisp
    connect Mdl_TurnHazard.pp_TurnHazard_TurnL_Sts -> Ctrl_WSS.rp_TurnHzdTurnL_Status
    connect Mdl_TurnHazard.pp_TurnHazard_TurnR_Sts -> Ctrl_WSS.rp_TurnHzdTurnR_Status
    connect CView_Telltale.ppTelltaleSts -> UclProxyCdd.rSR_TT_Status
    connect Mdl_Airbag.pp_Airbag_TT_Status -> CView_Telltale.rpTelltlaeStatus_rp_Airbag_TT_Status
    connect Mdl_TurnHazard.pp_TurnHazard_LeftInd_Sts -> CView_Telltale.rpTelltlaeStatus_rp_TurnHazard_LeftInd_Sts
    connect Mdl_TurnHazard.pp_TurnHazard_RightInd_Sts -> CView_Telltale.rpTelltlaeStatus_rp_TurnHazard_RightInd_Sts
    connect CWarnMsg_Core_Observer.pp_HUDWarningDisplay -> UclProxyCdd.rSR_HudWarningDisplay
    connect CWarnMsg_Core_Observer.pp_TPMSWarnPayload -> UclProxyCdd.rSR_TpmsWarningData
    connect CWarnMsg_Core_Observer.pp_WarningDisplay -> UclProxyCdd.rSR_WarningDisplay
    connect UclProxyCdd.pSR_HudWarningStatus -> CWarnMsg_Core_Observer.rp_HUDWarningStatus
    connect Mdl_Dim.pp_illumStarterstatus -> CWarnMsg_Core_Observer.rp_IllumStartSts
    connect UclProxyCdd.pSR_WarningStatus -> CWarnMsg_Core_Observer.rp_WarningStatus
    connect CComAbsMdl.pp_CmpLibCmd_CComAbsMdl -> EcuAppM.rp_CmpLibCmd_rp_CmpLibCmd_CComAbsMdl
    connect FastGaugeAdapter.pp_FastGaugeInfo -> UclProxyCdd.rSR_FastGaugeInfo
    connect Mdl_Tacho.pp_Analog_Tacho -> FastGaugeAdapter.rp_Analog_Tacho
    connect Mdl_Tacho.pp_Digital_Tacho -> FastGaugeAdapter.rp_Digital_Tacho
    connect View_Speed.pp_Display_speed_Value -> FastGaugeAdapter.rp_Display_speed_Value
    connect Mdl_Tacho.pp_Needle_Transparent -> FastGaugeAdapter.rp_Needle_Transparent
    connect View_Speed.pp_SubDisplaySpeed_Value -> FastGaugeAdapter.rp_SubDisplaySpeed_Value
    connect Mdl_Tacho.pp_TC_Unit -> FastGaugeAdapter.rp_TC_Unit
    connect Mdl_Tacho.pp_Tacho_RED_Start_RPM -> FastGaugeAdapter.rp_Tacho_RED_Start_RPM
    connect Mdl_Tacho.pp_Tacho_RPM_MAX -> FastGaugeAdapter.rp_Tacho_RPM_MAX
    connect Mdl_SafetyAdapter.pp_CS_RxCanSafe -> Mdl_Airbag.rp_CS_CanAdapterRx
    connect MemAbstractMdl.pp_CS_MemAbsSet -> Mdl_Dim.rp_CS_MemAbsSet
    connect Mdl_Gear.pp_Shiftpos_ShiftPosIndStatus -> UclProxyCdd.rSR_ShiftPosIndStatus
    connect Mdl_Linear_Interpolation.pp_LinearInterpolateWord -> Mdl_Speed.rp_CS_LinerInterpolation
    connect IoHwAb.ppIoHwAb_Din -> Mdl_SafetyAdapter.rp_IOHWab_Din
    connect Mdl_Speed.pp_SPD_SP1_In_Status -> View_Speed.rp_SPD_SP1_In_Status
    connect Mdl_Speed.pp_SPD_Selection_Table -> View_Speed.rp_SPD_Selection_Table
    connect Mdl_Speed.pp_SPD_Target2_Status -> View_Speed.rp_SPD_Target2_Status
    connect Mdl_Speed.pp_SPD_Target_Status -> View_Speed.rp_SPD_Target_Status
    connect Mdl_Speed.pp_SPD_Trim2_Status -> View_Speed.rp_SPD_Trim2_Status
    connect Mdl_Speed.pp_SPD_Trim_Status -> View_Speed.rp_SPD_Trim_Status
    connect IoHwAb.ppIoHwAb_ADC -> Mdl_Speed.rpIoHwAb_ADC
    connect SlowGaugeAdapter.pp_SlowGaugeInfo -> UclProxyCdd.rSR_SlowGaugeInfo
    connect TmExt.pp_CS_TmExt_Timer_IsElapsed -> WarnMsg_Core_TmrSupport.rp_CS_TmExt_Timer_Elapsed
    connect TmExt.pp_CS_TmExt_Timer_IsStarted -> WarnMsg_Core_TmrSupport.rp_CS_TmExt_Timer_Started
    connect MemAbstractMdl.pp_CS_MemAbsGet -> View_Speed.rp_CS_MemAbsGet
    connect CComAbsMdl.pp_CS_RxCanMdl -> View_Speed.rp_CS_RxCanMdl
    connect CComAbsMdl.pp_CS_TxCanMdl -> View_Speed.rp_CS_TxCanMdl
    connect TmExt.pp_CS_TmExt_Timer_Start -> WarnMsg_Core_TmrSupport.rp_CS_TmExt_Timer_Start
    connect TmExt.pp_CS_TmExt_Timer_Stop -> WarnMsg_Core_TmrSupport.rp_CS_TmExt_Timer_Stop
    connect Mdl_Airbag.pp_Airbag_TT_Status -> CCtrl_Telltale.rpTelltlaeStatus_rp_Airbag_TT_Status
    connect Mdl_TurnHazard.pp_TurnHazard_LeftInd_Sts -> CCtrl_Telltale.rpTelltlaeStatus_rp_TurnHazard_LeftInd_Sts
    connect Mdl_TurnHazard.pp_TurnHazard_RightInd_Sts -> CCtrl_Telltale.rpTelltlaeStatus_rp_TurnHazard_RightInd_Sts
    connect CBattMdl.ppSR_BattMdl_AVP -> Ctrl_Dim.rpSR_PowerCdd_AVP
    connect Ctrl_WSS.pp_AppMdl_Sleep -> Ctrl_Dim.rp_ILL_ReadyToSleep
    connect Ctrl_WSS.pp_TFTDisplayOn -> Ctrl_Dim.rp_TFTDisplayOn
    connect CCtrl_Telltale.ppTelltaleStatusOP -> Ctrl_WSS.rpTelltaleStatusOP
    connect CCtrl_Telltale.ppBlinkStatusArray -> Ctrl_WSS.rp_BlinkStsArray
    connect TmExt.pp_CS_TmExt_Timer_IsElapsed -> Ctrl_WSS.rp_CS_TmExt_Timer_Elapsed
    connect TmExt.pp_CS_TmExt_Timer_Start -> Ctrl_WSS.rp_CS_TmExt_Timer_Start
    connect TmExt.pp_CS_TmExt_Timer_IsStarted -> Ctrl_WSS.rp_CS_TmExt_Timer_Started
    connect TmExt.pp_CS_TmExt_Timer_Stop -> Ctrl_WSS.rp_CS_TmExt_Timer_Stop
    connect CComAbsMdl.pp_CS_TxCanMdl -> CWarnMsg_Core_Observer.rp_CS_TxCanMdl
    connect Ctrl_WSS.pp_HMIReady -> CWarnMsg_Core_Observer.rp_HMIReadySts
    connect IoHwAb.ppIoHwAb_Din -> Mdl_Dim.rpIoHwAb_Din
    connect Ctrl_WSS.pp_VehicleAppMode -> Mdl_Dim.rpVehicleAppMode
    connect Ctrl_WSS.pp_Variant_status -> Mdl_Dim.rp_Variant_Status
    connect IoHwAb.ppIoHwAb_ADC -> Mdl_SafetyAdapter.rp_IoHwAb_ADC
    connect MemAbstractMdl.pp_CS_MemAbsGet -> Mdl_Speed.rp_CS_MemAbsGet
    connect CComAbsMdl.pp_CS_RxCanMdl -> Mdl_Tacho.rp_CS_RxCanMdl
    connect Mdl_Speed.pp_SPD_SP1_In_Status -> Mdl_Tacho.rp_SPD_SP1_In_Status
    connect Ctrl_warning.ppCtrlWarningStatus -> Mdl_wAirbag.rpUpdateAirbagWarning
    connect Ctrl_WSS.ppIgnSubstate -> SlowGaugeAdapter.rpIgnSubstate
    connect Ctrl_WSS.pp_ClusterMode -> SlowGaugeAdapter.rp_ClusterMode
    connect Ctrl_WSS.pp_VehicleAppMode -> Ctrl_Dim.rpVehicleAppMode
    connect IoHwAb.ppIoHwAb_Din -> Ctrl_WSS.rpIoHwAb_Din
    connect MemAbstractMdl.pp_CS_MemAbsGet -> Mdl_Dim.rp_CS_MemAbsGet
    connect IoHwAb.ppIoHwAb_ADC -> Mdl_Dim.rp_IoHwAb_ADC
    connect CComAbsMdl.pp_CS_RxCanMdl -> Mdl_Gear.rp_CS_RxCanMdl
    connect Ctrl_WSS.ppIgnSubstate -> Mdl_wFuelLidOpen.rpIgnSubstate
    connect Ctrl_warning.ppCtrlWarningStatus -> Mdl_wFuelLidOpen.rpUpdateFuelLidOpenWarning
    connect Ctrl_WSS.pp_ClusterMode -> Mdl_wFuelLidOpen.rp_ClusterMode
    connect Ctrl_WSS.pp_HMIReady -> SlowGaugeAdapter.rp_HMIReadyState
    connect IoHwAb.ppIoHwAb_Din -> Ctrl_Dim.rpIoHwAb_Din
    connect MemAbstractMdl.pp_CS_MemAbsGet -> Ctrl_Dim.rp_CS_MemAbsGet
    connect IoHwAb.ppIoHwAb_ADC -> Ctrl_WSS.rpIoHwAb_ADC
    connect Ctrl_WSS.pp_HMIReady -> FastGaugeAdapter.rp_HMIReadyState
    connect CComAbsMdl.pp_CS_RxCanMdl -> Mdl_Dim.rp_CS_RxCanMdl
    connect Ctrl_WSS.ppIgnSubstate -> Mdl_wAirbag.rpIgnSubstate
    connect Ctrl_WSS.pp_ClusterMode -> Mdl_wAirbag.rp_ClusterMode
    connect Ctrl_WSS.pp_VehicleAppMode -> Mdl_wAirbag.rp_Vehiclestate
    connect CComAbsMdl.pp_CS_RxCanMdl -> Mdl_Airbag.rp_CS_CanRx
    connect Ctrl_WSS.pp_ClusterMode -> Mdl_Airbag.rp_ClusterMode
    connect Ctrl_WSS.ppIgnSubstate -> Mdl_Speed.rpIgnSubstate
    connect CComAbsMdl.pp_CS_RxCanMdl -> Mdl_Speed.rp_CS_CanRx
    connect Ctrl_WSS.pp_ClusterMode -> Mdl_Speed.rp_ClusterMode
    connect Ctrl_WSS.ppIgnSubstate -> Mdl_Gear.rpIgnSubstate
    connect CComAbsMdl.pp_CS_RxCanMdl -> Mdl_Gear.rp_CS_CanRx
    connect Ctrl_WSS.pp_ClusterMode -> Mdl_Gear.rp_ClusterMode
    connect Ctrl_WSS.pp_HMIReady -> Mdl_Gear.rp_HMI_Ready_Status
    connect Ctrl_WSS.pp_HMIReady -> CCtrl_Telltale.rpHmiReadyState
    connect CComAbsMdl.pp_CS_RxCanMdl -> Ctrl_WSS.rp_CS_RxCanMdl
    connect Ctrl_WSS.ppIgnSubstate -> Mdl_Tacho.rpIgnSubstate
    connect IoHwAb.ppIoHwAb_Din -> Mdl_TurnHazard.rpCS_IoHwAbInp
    connect Ctrl_WSS.pp_ClusterMode -> Mdl_TurnHazard.rp_ClusterMode
    connect Ctrl_WSS.ppIgnSubstate -> CCtrl_Telltale.rpIgnSubstate
    connect Ctrl_WSS.pp_ClusterMode -> CCtrl_Telltale.rp_ClusterMode
    connect Ctrl_WSS.ppIgnSubstate -> Mdl_Dim.rpIgnSubstate
    connect CComAbsMdl.pp_CS_RxCanMdl -> Mdl_Dim.rp_CS_CanRx
    connect Ctrl_WSS.pp_ClusterMode -> Mdl_Dim.rp_ClusterMode
    connect Ctrl_WSS.ppIgnSubstate -> Ctrl_warning.rpIgnSubstate
    connect Ctrl_WSS.pp_ClusterMode -> Ctrl_warning.rp_ClusterMode
    connect CComAbsMdl.pp_CS_RxCanMdl -> Ctrl_WSS.rp_CS_ComAbsRx
    connect Ctrl_WSS.pp_ClusterMode -> CView_Telltale.rp_ClusterMode
    connect Ctrl_WSS.ppIgnSubstate -> CWarnMsg_Core_Observer.rpIgnSubstate
    connect Ctrl_WSS.pp_ClusterMode -> CWarnMsg_Core_Observer.rp_ClusterMode
    connect Ctrl_WSS.ppIgnSubstate -> FastGaugeAdapter.rpIgnSubstate
    connect Ctrl_WSS.pp_ClusterMode -> FastGaugeAdapter.rp_ClusterMode
    connect Ctrl_WSS.pp_ClusterMode -> Mdl_SafetyAdapter.rp_ctrlwss_Clustermode
    connect Ctrl_WSS.pp_ClusterMode -> Mdl_Tacho.rp_ClusterMode
    connect CComAbsMdl.pp_CS_RxCanMdl -> Mdl_wAirbag.rp_CS_CanAdapterSafeRx
    connect CComAbsMdl.pp_CS_RxCanMdl -> Mdl_wFuelLidOpen.rp_CS_RxCanAdapterMdl
    connect CComAbsMdl.pp_CS_RxCanMdl -> CComAbsCtrl.rpCSRxCanMdl
    connect CComAbsMdl.pp_CS_TxCanMdl -> CComAbsCtrl.rpCSTxCanMdl
    connect IoHwAb.ppIoHwAb_Din -> CComAbsCtrl.rp_CS_IoHwAb_Din
    connect CDisplayCdd.ppSRDisplaySetPower -> UclProxyCdd.rSR_DisplaySetPower
    connect UclProxyCdd.pSR_DisplayCurrentState -> CDisplayCdd.rpSRDisplayCurrentState
    connect Ctrl_WSS.ppIgnSubstate -> Ctrl_Dim.rpIgnSubstate
    connect Ctrl_WSS.pp_ClusterMode -> Ctrl_Dim.rp_ClusterMode
    connect EcuMExt.ppCS_EcumExt_GetResetReason -> Dlt.rpCS_EcumExt_GetResetReason
    connect Ctrl_WSS.ppIgnSubstate -> Mdl_Airbag.rpIgnSubstate
    connect Ctrl_WSS.pp_VehicleAppMode -> Mdl_Airbag.rp_VehicleAppMode
    connect ComMExt.ppComMExt -> Ctrl_WSS.rpComMExt
    connect CorTst.pp_CmpLibCmd_CorTst -> EcuAppM.rp_CmpLibCmd_rp_CmpLibCmd_CorTst
    connect CComAbsMdl.pp_CS_RxCanMdl -> Ctrl_Dim.rp_CS_CanRx
    connect NvMExtSf.pp_CmpLibCmd_CNvMExtSf -> EcuAppM.rp_CmpLibCmd_rp_CmpLibCmd_CNvMExtSf
    connect FlsTst.pp_CmpLibCmd_FlsTst -> EcuAppM.rp_CmpLibCmd_rp_CmpLibCmd_FlsTst
    connect RamTst.pp_CmpLibCmd_RamTst -> EcuAppM.rp_CmpLibCmd_rp_CmpLibCmd_RamTst
    connect SysTst.pp_CmpLibCmd_SysTst -> EcuAppM.rp_CmpLibCmd_rp_CmpLibCmd_SysTst
    connect MemAbstractMdl.pp_CS_MemAbsGet -> NvMExtSf.rp_CS_MemAbsGet
    connect MemAbstractMdl.pp_CS_MemAbsSet -> NvMExtSf.rp_CS_MemAbsSet
    connect MemAbstractStub.BsFuSa_FeatureData_NvMNotifyJobFinished -> NvM.NvM_RpNotifyJobEnd_NvBlockSwComponentTypeNVBlockDescriptor_BsFuSa_FeatureData
    connect CDisplayCdd.pp_CmpLibCmd_CDisplayCdd -> EcuAppM.rp_CmpLibCmd_rp_CmpLibCmd_CDisplayCdd
    connect CFltM.pp_CmpLibCmd_CFltM -> EcuAppM.rp_CmpLibCmd_rp_CmpLibCmd_CFltM
    connect RstM.pp_CS_RstM_GetResetCount -> CFltM.rp_CS_RstM_GetResetCount
    connect RstM.pp_CS_RstM_RequestSwReset -> CFltM.rp_CS_RstM_RequestSwReset
    connect CUpdateCdd.pp_CS_UpdateCdd_GenericDIDRequestHandler -> DcmExt.rp_CS_UpdateCdd_DID_DiagAction
    connect CUpdateCdd.pp_CS_UpdateCdd_GenericDownloadRequestHandler -> DcmExt.rp_CS_UpdateCdd_Service_0x34_Handler
    connect CUpdateCdd.pp_CS_UpdateCdd_GenericRIDRequestHandler -> DcmExt.rp_CS_UpdateCdd_RID_DiagAction
    connect CUpdateCdd.pp_CS_UpdateCdd_GenericTransferDataHandler -> DcmExt.rp_CS_UpdateCdd_Service_0x36_Handler
    connect CUpdateCdd.pp_CS_UpdateCdd_GenericTransferExitHandler -> DcmExt.rp_CS_UpdateCdd_Service_0x37_Handler
    connect CUpdateCdd.pp_CmpLibCmd_CUpdateCdd -> EcuAppM.rp_CmpLibCmd_rp_CmpLibCmd_CUpdateCdd
    connect CUpdateCdd.pp_SR_UpdateLongServiceRequest -> UclProxyCdd.rSR_UpdateLongServiceReq
    connect CUpdateCdd.pp_SR_UpdateShortServiceRequest -> UclProxyCdd.rSR_UpdateShortServiceReq
    connect UclProxyCdd.pSR_UpdateShortServiceResp -> CUpdateCdd.rp_SR_UpdateShortServiceResponse
    connect SafeNvM.pp_CmpLibCmd_CSafeNvM -> EcuAppM.rp_CmpLibCmd_rp_CmpLibCmd_CSafeNvM
    connect UclProxyCdd.pSR_MainHMIReadyStatus -> Ctrl_WSS.rpUclHMIReadySts
    connect ComMExt.ppComMExt -> Mdl_SafetyAdapter.rpComMExt
    connect NvBlockSwComponentType.BsReten_Tripcomputer_Element -> MemAbstractStub.BsReten_Tripcomputer_Element  # UB:Derived from original system description
    connect NvBlockSwComponentType.BsConst_Derating_Backlight_Disable_SafeCopy1 -> MemAbstractStub.BsConst_Derating_Backlight_Disable_SafeCopy1  # UB:Derived from original system description
    connect NvBlockSwComponentType.BsConst_TripComputer_Element -> MemAbstractStub.BsConst_TripComputer_Element  # UB:Derived from original system description
    connect NvBlockSwComponentType.BsReten_Audio_Element -> MemAbstractStub.BsReten_Audio_Element  # UB:Derived from original system description
    connect NvBlockSwComponentType.BsConst_PWM_boost_bypass_duty_SafeCopy1 -> MemAbstractStub.BsConst_PWM_boost_bypass_duty_SafeCopy1  # UB:Derived from original system description
    connect NvBlockSwComponentType.BsShare_VisMeet_Element -> MemAbstractStub.BsShare_VisMeet_Element  # UB:Derived from original system description
    connect NvBlockSwComponentType.BsShare_VisteonPartNumber -> MemAbstractStub.BsShare_VisteonPartNumber  # UB:Derived from original system description
    connect NvBlockSwComponentType.BsShare_SwUpdFotadecrypt_Element -> MemAbstractStub.BsShare_SwUpdFotadecrypt_Element  # UB:Derived from original system description
    connect NvBlockSwComponentType.BsRt_Warning_Element -> MemAbstractStub.BsRt_Warning_Element  # UB:Derived from original system description
    connect NvBlockSwComponentType.BsShare_AssemblyPlantNumber -> MemAbstractStub.BsShare_AssemblyPlantNumber  # UB:Derived from original system description
    connect NvBlockSwComponentType.BsConst_PWM_boost_bypass_duty_SafeCopy2 -> MemAbstractStub.BsConst_PWM_boost_bypass_duty_SafeCopy2  # UB:Derived from original system description
    connect NvBlockSwComponentType.BsShare_SwUpdFotaStatus_Element -> MemAbstractStub.BsShare_SwUpdFotaStatus_Element  # UB:Derived from original system description
    connect NvBlockSwComponentType.BsConst_Temp_Threshold_Hysteresis_Derating_SafeCopy2 -> MemAbstractStub.BsConst_Temp_Threshold_Hysteresis_Derating_SafeCopy2  # UB:Derived from original system description
    connect NvBlockSwComponentType.BsReten_Illumination_Element -> MemAbstractStub.BsReten_Illumination_Element  # UB:Derived from original system description
    connect NvBlockSwComponentType.BsShare_AssemblyManufacturingDate -> MemAbstractStub.BsShare_AssemblyManufacturingDate  # UB:Derived from original system description
    connect NvBlockSwComponentType.BsRt_RealTimeClock_Element -> MemAbstractStub.BsRt_RealTimeClock_Element  # UB:Derived from original system description
    connect NvBlockSwComponentType.BsConst_Temp_Threshold_Hysteresis_Derating_SafeCopy1 -> MemAbstractStub.BsConst_Temp_Threshold_Hysteresis_Derating_SafeCopy1  # UB:Derived from original system description
    connect NvBlockSwComponentType.BsConst_Lookup_Curve_HotSpot_Coef_Y_SafeCopy2 -> MemAbstractStub.BsConst_Lookup_Curve_HotSpot_Coef_Y_SafeCopy2  # UB:Derived from original system description
    connect NvBlockSwComponentType.BsShare_SMTManufacturingDate -> MemAbstractStub.BsShare_SMTManufacturingDate  # UB:Derived from original system description
    connect NvBlockSwComponentType.BsConst_Temperature_Sensor_Conv_SafeCopy2 -> MemAbstractStub.BsConst_Temperature_Sensor_Conv_SafeCopy2  # UB:Derived from original system description
    connect NvBlockSwComponentType.BsConst_Compensation_Line_Slope_m_SafeCopy1 -> MemAbstractStub.BsConst_Compensation_Line_Slope_m_SafeCopy1  # UB:Derived from original system description
    connect NvBlockSwComponentType.BsConst_Compensation_Line_Shift_b_SafeCopy1 -> MemAbstractStub.BsConst_Compensation_Line_Shift_b_SafeCopy1  # UB:Derived from original system description
    connect NvBlockSwComponentType.BsRt_OilGauge_Element -> MemAbstractStub.BsRt_OilGauge_Element  # UB:Derived from original system description
    connect NvBlockSwComponentType.BsShare_SwUpdReflash_Element -> MemAbstractStub.BsShare_SwUpdReflash_Element  # UB:Derived from original system description
    connect NvBlockSwComponentType.BsReten_Power_Element -> MemAbstractStub.BsReten_Power_Element  # UB:Derived from original system description
    connect NvBlockSwComponentType.BsConst_Audio_Element -> MemAbstractStub.BsConst_Audio_Element  # UB:Derived from original system description
    connect NvBlockSwComponentType.BsShare_VisteonPCBPartNumber -> MemAbstractStub.BsShare_VisteonPCBPartNumber  # UB:Derived from original system description
    connect NvBlockSwComponentType.BsReten_Communication_Element -> MemAbstractStub.BsReten_Communication_Element  # UB:Derived from original system description
    connect NvBlockSwComponentType.BsConst_Display_Illum_Max_Level_SafeCopy1 -> MemAbstractStub.BsConst_Display_Illum_Max_Level_SafeCopy1  # UB:Derived from original system description
    connect NvBlockSwComponentType.BsConst_RealTimeClock_Element -> MemAbstractStub.BsConst_RealTimeClock_Element  # UB:Derived from original system description
    connect NvBlockSwComponentType.BsReten_Warning_Element -> MemAbstractStub.BsReten_Warning_Element  # UB:Derived from original system description
    connect NvBlockSwComponentType.BsRt_SpeedoGauge_Element -> MemAbstractStub.BsRt_SpeedoGauge_Element  # UB:Derived from original system description
    connect NvBlockSwComponentType.BsDiag_Dtc_Element -> MemAbstractStub.BsDiag_Dtc_Element  # UB:Derived from original system description
    connect NvBlockSwComponentType.BsReten_Gauges_Element -> MemAbstractStub.BsReten_Gauges_Element  # UB:Derived from original system description
    connect NvBlockSwComponentType.BsRt_Odometer_Element -> MemAbstractStub.BsRt_Odometer_Element  # UB:Derived from original system description
    connect NvBlockSwComponentType.BsRt_FuelGauge_Element -> MemAbstractStub.BsRt_FuelGauge_Element  # UB:Derived from original system description
    connect NvBlockSwComponentType.BsRt_Illumination_Element -> MemAbstractStub.BsRt_Illumination_Element  # UB:Derived from original system description
    connect NvBlockSwComponentType.RefCys_Certicificate1_Element -> MemAbstractStub.RefCys_Certicificate1_Element  # UB:Derived from original system description
    connect NvBlockSwComponentType.BsConst_PCB_Temperature_Sensor_Conv_SafeCopy2 -> MemAbstractStub.BsConst_PCB_Temperature_Sensor_Conv_SafeCopy2  # UB:Derived from original system description
    connect NvBlockSwComponentType.BsConst_Temperature_Sensor_Conv_SafeCopy1 -> MemAbstractStub.BsConst_Temperature_Sensor_Conv_SafeCopy1  # UB:Derived from original system description
    connect NvBlockSwComponentType.BsShare_HWModification -> MemAbstractStub.BsShare_HWModification  # UB:Derived from original system description
    connect NvBlockSwComponentType.BsConst_Compensation_Line_Slope_m_SafeCopy2 -> MemAbstractStub.BsConst_Compensation_Line_Slope_m_SafeCopy2  # UB:Derived from original system description
    connect NvBlockSwComponentType.BsConst_Communication_Element -> MemAbstractStub.BsConst_Communication_Element  # UB:Derived from original system description
    connect NvBlockSwComponentType.BsRt_TempGauge_Element -> MemAbstractStub.BsRt_TempGauge_Element  # UB:Derived from original system description
    connect NvBlockSwComponentType.BsRt_CusDlt_Element -> MemAbstractStub.BsRt_CusDlt_Element  # UB:Derived from original system description
    connect NvBlockSwComponentType.BsConst_BsConst_Illumination_ReservedByte_SafeCopy1 -> MemAbstractStub.BsConst_BsConst_Illumination_ReservedByte_SafeCopy1  # UB:Derived from original system description
    connect NvBlockSwComponentType.BsConst_EngOffTimer_Element -> MemAbstractStub.BsConst_EngOffTimer_Element  # UB:Derived from original system description
    connect NvBlockSwComponentType.BsConst_PCB_Temperature_Sensor_Conv_SafeCopy1 -> MemAbstractStub.BsConst_PCB_Temperature_Sensor_Conv_SafeCopy1  # UB:Derived from original system description
    connect NvBlockSwComponentType.BsRt_PowerGauge_Element -> MemAbstractStub.BsRt_PowerGauge_Element  # UB:Derived from original system description
    connect NvBlockSwComponentType.BsConst_Warning_Element -> MemAbstractStub.BsConst_Warning_Element  # UB:Derived from original system description
    connect NvBlockSwComponentType.BsConst_TachoGauge_Element -> MemAbstractStub.BsConst_TachoGauge_Element  # UB:Derived from original system description
    connect NvBlockSwComponentType.BsConst_ServiceReminder_Element -> MemAbstractStub.BsConst_ServiceReminder_Element  # UB:Derived from original system description
    connect NvBlockSwComponentType.BsConst_Lookup_Curve_HotSpot_Coef_X_SafeCopy1 -> MemAbstractStub.BsConst_Lookup_Curve_HotSpot_Coef_X_SafeCopy1  # UB:Derived from original system description
    connect NvBlockSwComponentType.BsDiag_ErrorRecord_Element -> MemAbstractStub.BsDiag_ErrorRecord_Element  # UB:Derived from original system description
    connect NvBlockSwComponentType.BsConst_SpeedoGauge_Element -> MemAbstractStub.BsConst_SpeedoGauge_Element  # UB:Derived from original system description
    connect NvBlockSwComponentType.BsShare_EcuPartNumber_Element -> MemAbstractStub.BsShare_EcuPartNumber_Element  # UB:Derived from original system description
    connect NvBlockSwComponentType.BsShare_SwUpdFotaMode_Element -> MemAbstractStub.BsShare_SwUpdFotaMode_Element  # UB:Derived from original system description
    connect NvBlockSwComponentType.BsReten_Display_Element -> MemAbstractStub.BsReten_Display_Element  # UB:Derived from original system description
    connect NvBlockSwComponentType.BsConst_OilGauge_Element -> MemAbstractStub.BsConst_OilGauge_Element  # UB:Derived from original system description
    connect NvBlockSwComponentType.BsConst_Power_Element -> MemAbstractStub.BsConst_Power_Element  # UB:Derived from original system description
    connect NvBlockSwComponentType.BsShare_ProductSerialNumber -> MemAbstractStub.BsShare_ProductSerialNumber  # UB:Derived from original system description
    connect NvBlockSwComponentType.BsShare_PCBSerialNumber -> MemAbstractStub.BsShare_PCBSerialNumber  # UB:Derived from original system description
    connect NvBlockSwComponentType.BsRt_TripComputer_Element -> MemAbstractStub.BsRt_TripComputer_Element  # UB:Derived from original system description
    connect NvBlockSwComponentType.BsReten_Odometer_Element -> MemAbstractStub.BsReten_Odometer_Element  # UB:Derived from original system description
    connect NvBlockSwComponentType.BsConst_Display_Illum_Max_Level_SafeCopy2 -> MemAbstractStub.BsConst_Display_Illum_Max_Level_SafeCopy2  # UB:Derived from original system description
    connect NvBlockSwComponentType.BsRt_Personalization_Element -> MemAbstractStub.BsRt_Personalization_Element  # UB:Derived from original system description
    connect NvBlockSwComponentType.BsReten_RealTimeClock_Element -> MemAbstractStub.BsReten_RealTimeClock_Element  # UB:Derived from original system description
    connect NvBlockSwComponentType.BsConst_FuelGauge_Element -> MemAbstractStub.BsConst_FuelGauge_Element  # UB:Derived from original system description
    connect NvBlockSwComponentType.RefCys_Certicificate_Element -> MemAbstractStub.RefCys_Certicificate_Element  # UB:Derived from original system description
    connect NvBlockSwComponentType.BsConst_PowerGauge_Element -> MemAbstractStub.BsConst_PowerGauge_Element  # UB:Derived from original system description
    connect NvBlockSwComponentType.BsShare_SwUpdFotaFinPrint_Element -> MemAbstractStub.BsShare_SwUpdFotaFinPrint_Element  # UB:Derived from original system description
    connect NvBlockSwComponentType.BsCys_Certicificate_Element -> MemAbstractStub.BsCys_Certicificate_Element  # UB:Derived from original system description
    connect NvBlockSwComponentType.BsConst_Lookup_Curve_HotSpot_Coef_X_SafeCopy2 -> MemAbstractStub.BsConst_Lookup_Curve_HotSpot_Coef_X_SafeCopy2  # UB:Derived from original system description
    connect NvBlockSwComponentType.BsShare_SMTPlantNumber -> MemAbstractStub.BsShare_SMTPlantNumber  # UB:Derived from original system description
    connect NvBlockSwComponentType.BsRt_TachoGauge_Element -> MemAbstractStub.BsRt_TachoGauge_Element  # UB:Derived from original system description
    connect NvBlockSwComponentType.BsConst_Lookup_Curve_HotSpot_Coef_Y_SafeCopy1 -> MemAbstractStub.BsConst_Lookup_Curve_HotSpot_Coef_Y_SafeCopy1  # UB:Derived from original system description
    connect NvBlockSwComponentType.BsReten_Personalization_Element -> MemAbstractStub.BsReten_Personalization_Element  # UB:Derived from original system description
    connect NvBlockSwComponentType.BsConst_TempGauge_Element -> MemAbstractStub.BsConst_TempGauge_Element  # UB:Derived from original system description
    connect NvBlockSwComponentType.BsConst_Compensation_Line_Shift_b_SafeCopy2 -> MemAbstractStub.BsConst_Compensation_Line_Shift_b_SafeCopy2  # UB:Derived from original system description
    connect NvBlockSwComponentType.BsShare_VisMeet_EOLEntry_Element -> MemAbstractStub.BsShare_VisMeet_EOLEntry_Element  # UB:Derived from original system description
    connect NvBlockSwComponentType.BsConst_Derating_Backlight_Disable_SafeCopy2 -> MemAbstractStub.BsConst_Derating_Backlight_Disable_SafeCopy2  # UB:Derived from original system description
    connect NvBlockSwComponentType.BsShare_VehicleConfig_Element -> MemAbstractStub.BsShare_VehicleConfig_Element  # UB:Derived from original system description
    connect NvBlockSwComponentType.BsConst_BsConst_Illumination_ReservedByte_SafeCopy2 -> MemAbstractStub.BsConst_BsConst_Illumination_ReservedByte_SafeCopy2  # UB:Derived from original system description
    connect MemAbstractStub.BsConst_Illumination_Copy1_NvMNotifyJobFinished -> NvM.NvM_RpNotifyJobEnd_NvBlockSwComponentTypeNVBlockDescriptor_BsConst_Illumination_Copy1
    connect MemAbstractStub.BsConst_Illumination_Copy2_NvMNotifyJobFinished -> NvM.NvM_RpNotifyJobEnd_NvBlockSwComponentTypeNVBlockDescriptor_BsConst_Illumination_Copy2
    connect MemAbstract_Stub_Safe.BsConst_Illumination_NvMNotifyJobFinished -> NvM.NvM_RpNotifyJobEnd_NvBlockSwComponentTypeNVBlockDescriptor_BsConst_Illumination
    connect MemAbstract_Stub_Safe.BsConst_Illumination_Copy1_NvMNotifyJobFinished -> NvM.NvM_RpNotifyJobEnd_NvBlockSwComponentTypeNVBlockDescriptor_BsConst_Illumination_Copy1
    connect MemAbstract_Stub_Safe.BsConst_Illumination_Copy2_NvMNotifyJobFinished -> NvM.NvM_RpNotifyJobEnd_NvBlockSwComponentTypeNVBlockDescriptor_BsConst_Illumination_Copy2
    connect EcuMExt.ppCS_EcumExt_RequestRUN -> CCDD_McuFit.rpCS_EcumExt_RequestRUN
    connect EcuMExt.ppCS_EcumExt_RequestRUN -> CCDD_BswFit.rpCS_EcumExt_RequestRUN
    connect ComMExt.ppComMExt -> CComAbsCtrl.rpCSComMExt
    connect DemExt.pp_CS_DemExt_SetEventStatus -> CFltM.rp_CS_DemExt_SetEventStatus
    connect CFltM.pp_CS_FltM_ReportFault -> CFltMExt.rp_CS_FltM_ReportFault
    connect RstM.pp_CS_RstM_ClearResetHistory -> CFltM.rp_CS_RstM_ClearResetHistory
    connect RstM.pp_CS_RstM_GetLastResetReason -> CFltM.rp_CS_RstM_GetLastResetReason
    connect RstM.pp_CS_RstM_GetResetHistory -> CFltM.rp_CS_RstM_GetResetHistory
    connect CFltMExt.pp_CmpLibCmd_CFltMExt -> EcuAppM.rp_CmpLibCmd_rp_CmpLibCmd_CFltMExt
    connect CBattMdl.ppSR_BattMdl_AVP -> CFltMExt.rpSR_BattMdl_AVP
    connect Ctrl_Illumination.pp_IllumCtrl_Op -> View_Illumination.rp_IllumCtrl_Op
    connect CComAbsMdl.pp_CS_RxCanMdl -> Ctrl_Illumination.rp_CS_CanRx
    connect Ctrl_WSS.pp_ClusterMode -> Ctrl_Illumination.rp_ClusterMode
    connect Ctrl_WSS.pp_AppMdl_Sleep -> Ctrl_Illumination.rp_ILL_ReadyToSleep
    connect Mdl_Dim.pp_IllumCtrl_Ip -> Ctrl_Illumination.rp_IllumCtrl_Ip
    connect Mdl_Dim.pp_IlumStep -> Ctrl_Illumination.rp_IlumStep
    connect Dlt.ppCS_Dlt_SendLogMessage -> RstM.rp_CS_Dlt_SendLogMessage
    connect DltExt.ppCs_DltExt_GetResetInfo -> RstM.rp_CS_DltExt_GetResetInfo
    connect Ctrl_WSS.ppIgnSubstate -> View_Illumination.rpIgnSubstate
    connect IoHwAb.ppIoHwAb_Din -> View_Illumination.rpIoHwAb_Din
    connect Ctrl_WSS.pp_VehicleAppMode -> View_Illumination.rpVehicleAppMode
    connect MemAbstractMdl.pp_CS_MemAbsGet -> View_Illumination.rp_CS_MemAbsGet
    connect IoHwAb.ppIoHwAb_PWM -> View_Illumination.rp_PwmSetDuty
    connect Mdl_Dim.pp_RheostatDayStep -> View_Illumination.rp_RheostatDayStep
    connect Mdl_Dim.pp_RheostatNightStep -> View_Illumination.rp_RheostatNightStep
    connect Mdl_Dim.pp_illum_rheostat_change -> View_Illumination.rp_Rheostat_Change
    connect Ctrl_WSS.pp_TFTDisplayOn -> View_Illumination.rp_TFTDisplayOn
    connect TmExt.pp_CS_TmExt_Timer_IsElapsed -> View_Illumination.rp_TmExt_Timer_IsElapsed
    connect TmExt.pp_CS_TmExt_Timer_IsStarted -> View_Illumination.rp_TmExt_Timer_IsStarted
    connect TmExt.pp_CS_TmExt_Timer_Start -> View_Illumination.rp_TmExt_Timer_Start
    connect TmExt.pp_CS_TmExt_Timer_Stop -> View_Illumination.rp_TmExt_Timer_Stop
    connect Dlt.ppCS_Dlt_SendLogMessage -> CFltM.rp_CS_Dlt_SendLogMessage
    connect CMeetCdd.pSR_DiagDIDRequest -> UclProxyCdd.rSR_DiagDIDRequest
    connect CMeetCdd.pSR_DiagIOCtrlRequest -> UclProxyCdd.rSR_DiagIOCtrlRequest
    connect CMeetCdd.pSR_DiagRoutineRequest -> UclProxyCdd.rSR_DiagRoutineRequest
    connect UclProxyCdd.pSR_DiagResponse -> CMeetCdd.rSR_DiagResponse
    connect EcuAppM.ppSRPhasedRead_Status_phase1readcompleted -> Ctrl_WSS.rpSRPhasedRead_Status_phase1readcompleted
    connect EcuAppM.ppSRPhasedRead_Status_phase2readcompleted -> Ctrl_WSS.rpSRPhasedRead_Status_phase2readcompleted
    connect Ctrl_WSS.ppIgnSubstate -> Ctrl_Illumination.rpIgnSubstate
    connect IoHwAb.ppIoHwAb_Din -> Ctrl_Illumination.rpIoHwAb_Din
    connect Ctrl_WSS.pp_VehicleAppMode -> Ctrl_Illumination.rpVehicleAppMode
    connect MemAbstractMdl.pp_CS_MemAbsGet -> Ctrl_Illumination.rp_CS_MemAbsGet
    connect IoHwAb.ppIoHwAb_PWM -> Ctrl_Illumination.rp_PwmSetDuty
    connect Mdl_Dim.pp_RheostatDayStep -> Ctrl_Illumination.rp_RheostatDayStep
    connect Mdl_Dim.pp_RheostatNightStep -> Ctrl_Illumination.rp_RheostatNightStep
    connect Mdl_Dim.pp_illum_rheostat_change -> Ctrl_Illumination.rp_Rheostat_Change
    connect Ctrl_WSS.pp_TFTDisplayOn -> Ctrl_Illumination.rp_TFTDisplayOn
    connect TmExt.pp_CS_TmExt_Timer_IsElapsed -> Ctrl_Illumination.rp_TmExt_Timer_IsElapsed
    connect TmExt.pp_CS_TmExt_Timer_IsStarted -> Ctrl_Illumination.rp_TmExt_Timer_IsStarted
    connect TmExt.pp_CS_TmExt_Timer_Start -> Ctrl_Illumination.rp_TmExt_Timer_Start
    connect TmExt.pp_CS_TmExt_Timer_Stop -> Ctrl_Illumination.rp_TmExt_Timer_Stop
    connect CBattMdl.ppSR_BattMdl_AVP -> View_Illumination.rpSR_PowerCdd_AVP
    connect CComAbsMdlSafe.pp_Airbag -> CComAbsMdl_stubs.rp_SR_RxAirbag
    connect CComAbsMdlSafe.pp_CmpLibCmd_CComAbsMdlSafe -> EcuAppM.rp_CmpLibCmd_rp_CmpLibCmd_CComAbsMdlSafe
    connect MemAbstractMdl.pp_CS_MemAbsGet -> CComAbsMdlSafe.rp_CS_MemAbsGet
    connect CBattMdl.ppSR_BattMdl_AVP -> Ctrl_Illumination.rpSR_PowerCdd_AVP
    connect CCtrl_Telltale.pp_CmpLibCmd -> EcuAppM.rp_CmpLibCmd_rp_CmpLibCmd_CCtrl_Telltale
    connect CView_Telltale.pp_CmpLibCmd -> EcuAppM.rp_CmpLibCmd_rp_CmpLibCmd_CView_Telltale
    connect CWarnMsg_Core_Observer.pp_CmpLibCmd -> EcuAppM.rp_CmpLibCmd_rp_CmpLibCmd_CWarnMsg_Core_Observer
    connect Ctrl_WSS.pp_CmpLibCmd -> EcuAppM.rp_CmpLibCmd_rp_CmpLibCmd_Ctrl_WSS
    connect Ctrl_Illumination.pp_CmpLibCmd -> EcuAppM.rp_CmpLibCmd_rp_CmpLibCmd_Ctrl_Illumination
    connect View_Illumination.pp_CmpLibCmd -> EcuAppM.rp_CmpLibCmd_rp_CmpLibCmd_View_Illumination
    connect RstM.pp_CmpLibCmd_RstM -> EcuAppM.rp_CmpLibCmd_rp_CmpLibCmd_RstM
    connect NvMExt.ppSRPhasedRead_Status_phase{1..3}readcompleted -> Ctrl_WSS.rpSRPhasedRead_Status_phase{1..3}readcompleted
    connect Ctrl_Illumination.pp_CmpLibCmd_CCtrl_Illumination -> EcuAppM.rp_CmpLibCmd_rp_CmpLibCmd_CCtrl_Illumination
    connect View_Illumination.pp_CmpLibCmd_CView_Illumination -> EcuAppM.rp_CmpLibCmd_rp_CmpLibCmd_CView_Illumination
    connect NvBlockSwComponentType.BsConst_PCB_Temperature_Sensor_Conv -> MemAbstractStub.BsConst_PCB_Temperature_Sensor_Conv  # UB:Derived from original system description
    connect NvBlockSwComponentType.BsConst_Compensation_Line_Shift_b -> MemAbstractStub.BsConst_Compensation_Line_Shift_b  # UB:Derived from original system description
    connect NvBlockSwComponentType.BsConst_Lookup_Curve_HotSpot_Coef_X -> MemAbstractStub.BsConst_Lookup_Curve_HotSpot_Coef_X  # UB:Derived from original system description
    connect NvBlockSwComponentType.BsConst_Derating_Backlight_Disable -> MemAbstractStub.BsConst_Derating_Backlight_Disable  # UB:Derived from original system description
    connect NvBlockSwComponentType.BsConst_Lookup_Curve_HotSpot_Coef_Y -> MemAbstractStub.BsConst_Lookup_Curve_HotSpot_Coef_Y  # UB:Derived from original system description
    connect NvBlockSwComponentType.BsConst_Temp_Threshold_Hysteresis_Derating -> MemAbstractStub.BsConst_Temp_Threshold_Hysteresis_Derating  # UB:Derived from original system description
    connect NvBlockSwComponentType.BsConst_Display_Illum_Max_Level -> MemAbstractStub.BsConst_Display_Illum_Max_Level  # UB:Derived from original system description
    connect NvBlockSwComponentType.BsConst_PWM_boost_bypass_duty -> MemAbstractStub.BsConst_PWM_boost_bypass_duty  # UB:Derived from original system description
    connect NvBlockSwComponentType.BsConst_Temperature_Sensor_Conv -> MemAbstractStub.BsConst_Temperature_Sensor_Conv  # UB:Derived from original system description
    connect NvBlockSwComponentType.BsConst_Compensation_Line_Slope_m -> MemAbstractStub.BsConst_Compensation_Line_Slope_m  # UB:Derived from original system description
    connect NvBlockSwComponentType.BsConst_BsConst_Illumination_ReservedByte -> MemAbstractStub.BsConst_BsConst_Illumination_ReservedByte  # UB:Derived from original system description
    connect CUpdateCdd.pp_CS_UpdateCdd_GenericProgSessionRequest -> DcmExt.rp_CS_UpdateCdd_Service_0x10_Handler
    connect DltExt.pSR_DLTControlMessageReponse -> UclProxyCdd.rSR_DLTControlMessageReponse
    connect DltExt.pSR_DLTMessageReadRequest -> UclProxyCdd.rSR_DLTMessageReadRequest
    connect UclProxyCdd.pSR_DLTControlMessageRequest -> DltExt.rSR_DLTControlMessageRequest
    connect UclProxyCdd.pSR_DLTMessageReadAck -> DltExt.rSR_DLTMessageReadAck
    connect CWarnMsg_Core_Observer.pp_Init -> Ctrl_WSS.rp_Init_rp_Init_CWarnMsg_Core_Observer
    connect Ctrl_warning.pp_Init -> Ctrl_WSS.rp_Init_rp_Init_Ctrl_warning
    connect FastGaugeAdapter.pp_Init -> Ctrl_WSS.rp_Init_rp_Init_FastGaugeAdapter
    connect Mdl_Dim.pp_Init -> Ctrl_WSS.rp_Init_rp_Init_Mdl_Dim
    connect Mdl_Gear.pp_Init -> Ctrl_WSS.rp_Init_rp_Init_Mdl_Gear
    connect Mdl_Linear_Interpolation.pp_Init -> Ctrl_WSS.rp_Init_rp_Init_Mdl_Linear_Interpolation
    connect Mdl_Speed.pp_Init -> Ctrl_WSS.rp_Init_rp_Init_Mdl_Speed
    connect Mdl_Tacho.pp_Init -> Ctrl_WSS.rp_Init_rp_Init_Mdl_Tacho
    connect Mdl_TurnHazard.pp_Init -> Ctrl_WSS.rp_Init_rp_Init_Mdl_TurnHazard
    connect Mdl_wAirbag.pp_Init -> Ctrl_WSS.rp_Init_rp_Init_Mdl_wAirbag
    connect Mdl_wFuelLidOpen.pp_Init -> Ctrl_WSS.rp_Init_rp_Init_Mdl_wFuelLidOpen
    connect SlowGaugeAdapter.pp_Init -> Ctrl_WSS.rp_Init_rp_Init_SlowGaugeAdapter
    connect View_Speed.pp_Init -> Ctrl_WSS.rp_Init_rp_Init_View_Speed
    connect WarnMsg_Core_TmrSupport.pp_Init -> Ctrl_WSS.rp_Init_rp_Init_WarnMsg_Core_TmrSupport
    connect Ctrl_WSS.pp_SleepOperation -> EcuAppM.rp_CS_SleepOperation
    connect Ctrl_Illumination.pp_Init -> Ctrl_WSS.rp_Init_rp_Init_Ctrl_Illumination
    connect CComAbsMdlSafe.pp_CS_RxCanMdlSafe -> Mdl_Airbag.rp_CS_CanAdapterRx
    connect CRstM.pp_CS_RstM_ClearResetHistory -> CFltM.rp_CS_RstM_ClearResetHistory
    connect CRstM.pp_CS_RstM_GetLastResetReason -> CFltM.rp_CS_RstM_GetLastResetReason
    connect CRstM.pp_CS_RstM_GetResetCount -> CFltM.rp_CS_RstM_GetResetCount
    connect CRstM.pp_CS_RstM_GetResetHistory -> CFltM.rp_CS_RstM_GetResetHistory
    connect CRstM.pp_CS_RstM_RequestSwReset -> CFltM.rp_CS_RstM_RequestSwReset
    connect CRstM.pp_CmpLibCmd_RstM -> EcuAppM.rp_CmpLibCmd_rp_CmpLibCmd_RstM
    connect DltExt.ppCs_DltExt_GetResetInfo -> CRstM.rp_CS_DltExt_GetResetInfo
    connect Dlt.ppCS_Dlt_SendLogMessage -> CRstM.rp_CS_Dlt_SendLogMessage
    connect CComAbsMdl.pp_CS_RxCanMdl -> Mdl_TurnHazard.rp_CS_CanRx
    connect CRstM.pp_CmpLibCmd_CRstM -> EcuAppM.rp_CmpLibCmd_rp_CmpLibCmd_CRstM
    delegate CComAbsMdl_stubs.rp_SR_RxEngineSpeed_1 <-> outer port rp_SR_RxEngineSpeed  # UB:Derived from original system description
    delegate CComAbsMdl_stubs.rp_SR_RxTurn_Indicator_Control_1 <-> outer port rp_SR_RxTurn_Indicator_Control  # UB:Derived from original system description
    connect Ctrl_WSS.pp_NotifySleepStatus -> EcuAppM.rp_NotifySleepStatus
    connect IoHwAb.ppIoHwAb_ADC -> CCDD_EcuBatteryM.rpIoHwAb_ADC
    connect IoHwAb.ppIoHwAb_DOut -> CCDD_EcuBatteryM.rpIoHwAb_DOut
    connect IoHwAb.ppIoHwAb_Din -> CCDD_EcuBatteryM.rpIoHwAb_Din
    connect IoHwAb.ppIoHwAb_PWM -> CCDD_EcuBatteryM.rpIoHwAb_PWM
    connect CSigCdd.pp_SigCddCrc -> CSwcDispMonSf.rp_SigCddCrc
    connect CSigCdd.pp_SigCddSts -> CSwcDispMonSf.rp_SigCddSts
    connect CSwcDispMonSf.pp_SigData -> CSigCdd.rp_SigData
    connect CSwcDispMonSf.pp_CmpLibCmd_CSwcDispMonSf -> EcuAppM.rp_CmpLibCmd_rp_CmpLibCmd_CSwcDispMonSf
    connect CCDD_EcuBatteryM.pp_CmpLibCmd -> EcuAppM.rp_CmpLibCmd_rp_CmpLibCmd_CCDD_EcuBatteryM
    connect CSigCdd.pp_CmpLibCmd_CSigCdd -> EcuAppM.rp_CmpLibCmd_rp_CmpLibCmd_CSigCdd
    connect SafeNvM.pp_CmpLibCmd_CSafeNvM -> EcuAppM.rp_CmpLibCmd_rp_CmpLibCmd_CSndCdd
    connect CCDD_EcuBatteryM.ppCS_EcuBatteryOutData -> Ctrl_Illumination.rp_CS_EcuBatteryOutData
    connect CCDD_EcuBatteryM.ppCS_EcuBatteryOutData -> CFltMExt.rp_CS_EcuBatteryOutData
    connect CCDD_EcuBatteryM.ppCS_EcuBatteryOutData -> View_Illumination.rp_CS_EcuBatteryOutData
    connect CCDD_EcuBatteryM.ppCS_EcuBatteryOutData -> CCtrl_Telltale.rp_CS_EcuBatteryOutData
    connect MemAbstract_Stub_Safe.BsConst_Temp_Threshold_Hysteresis_Derating -> SafeNvM.BsConst_Temp_Threshold_Hysteresis_Derating  # UB:Derived from original system description
    connect MemAbstract_Stub_Safe.BsConst_Lookup_Curve_HotSpot_Coef_X -> SafeNvM.BsConst_Lookup_Curve_HotSpot_Coef_X  # UB:Derived from original system description
    connect MemAbstract_Stub_Safe.BsConst_Compensation_Line_Slope_m -> SafeNvM.BsConst_Compensation_Line_Slope_m  # UB:Derived from original system description
    connect MemAbstract_Stub_Safe.BsConst_PWM_boost_bypass_duty -> SafeNvM.BsConst_PWM_boost_bypass_duty  # UB:Derived from original system description
    connect MemAbstract_Stub_Safe.BsConst_Temperature_Sensor_Conv -> SafeNvM.BsConst_Temperature_Sensor_Conv  # UB:Derived from original system description
    connect MemAbstract_Stub_Safe.BsConst_BsConst_Illumination_ReservedByte -> SafeNvM.BsConst_BsConst_Illumination_ReservedByte  # UB:Derived from original system description
    connect MemAbstract_Stub_Safe.BsConst_Lookup_Curve_HotSpot_Coef_Y -> SafeNvM.BsConst_Lookup_Curve_HotSpot_Coef_Y  # UB:Derived from original system description
    connect MemAbstract_Stub_Safe.BsConst_Compensation_Line_Shift_b -> SafeNvM.BsConst_Compensation_Line_Shift_b  # UB:Derived from original system description
    connect MemAbstract_Stub_Safe.BsConst_Display_Illum_Max_Level_Safe -> SafeNvM.BsConst_Display_Illum_Max_Level_Safe  # UB:Derived from original system description
    connect MemAbstract_Stub_Safe.BsConst_PCB_Temperature_Sensor_Conv -> SafeNvM.BsConst_PCB_Temperature_Sensor_Conv  # UB:Derived from original system description
    connect MemAbstract_Stub_Safe.BsConst_Derating_Backlight_Disable -> SafeNvM.BsConst_Derating_Backlight_Disable  # UB:Derived from original system description
    connect CBacklightCdd.pp_CS_Backlight_service -> View_Illumination.rp_CS_Backlight_service
  end to end protection set E2EPROTECTIONSET
  port interface mapping set PORTINTERFACEMAPPINGSET
